AUTOSAR XML (schema 4-0-3)
standard types defined: uint8, Boolean, UInt16, UInt32, UInt8
package /AUTOSAR_Platform/DataConstrs
  range DC_Boolean: raw 0..1
  range DC_UInt16: raw 0..65535
  range DC_UInt8: raw 0..255
package /PATAC/Facility/DataTypes/Implementation
  compu method COMPU_Boolean: 0=FALSE, 1=TRUE
  unit NoUnit: factor-si-to-unit=1, offset-si-to-unit=0
package /PATAC/MSM/ComponentTypes
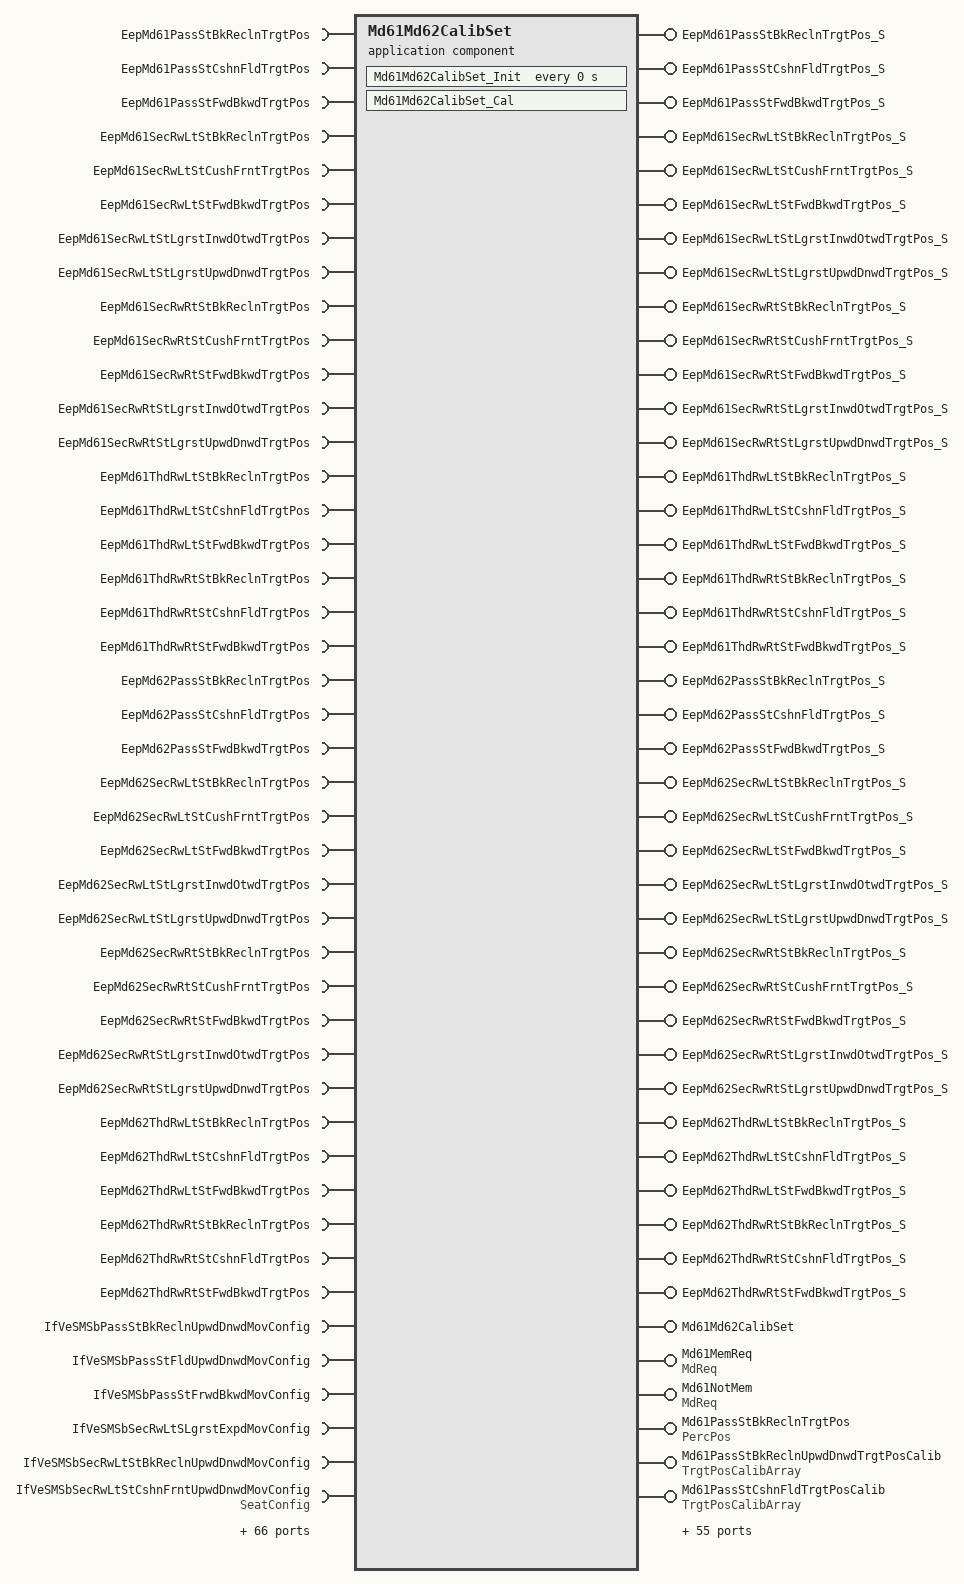
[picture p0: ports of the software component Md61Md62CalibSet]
  application sw component type Md61Md62CalibSet
    99 x provide port:
      EepMd61PassStBkReclnTrgtPos_S: nonqueued-sender-com-spec{data-element=EepMd61PassStBkReclnTrgtPos_S/Val, init-value=4095}, provided-interface=EepMd61PassStBkReclnTrgtPos_S
      EepMd61PassStCshnFldTrgtPos_S: nonqueued-sender-com-spec{data-element=EepMd61PassStCshnFldTrgtPos_S/Val, init-value=4095}, provided-interface=EepMd61PassStCshnFldTrgtPos_S
      EepMd61PassStFwdBkwdTrgtPos_S: nonqueued-sender-com-spec{data-element=EepMd61PassStFwdBkwdTrgtPos_S/Val, init-value=4095}, provided-interface=EepMd61PassStFwdBkwdTrgtPos_S
      EepMd61SecRwLtStBkReclnTrgtPos_S: nonqueued-sender-com-spec{data-element=EepMd61SecRwLtStBkReclnTrgtPos_S/Val, init-value=4095}, provided-interface=EepMd61SecRwLtStBkReclnTrgtPos_S
      EepMd61SecRwLtStCushFrntTrgtPos_S: nonqueued-sender-com-spec{data-element=EepMd61SecRwLtStCushFrntTrgtPos_S/Val, init-value=4095}, provided-interface=EepMd61SecRwLtStCushFrntTrgtPos_S
      EepMd61SecRwLtStFwdBkwdTrgtPos_S: nonqueued-sender-com-spec{data-element=EepMd61SecRwLtStFwdBkwdTrgtPos_S/Val, init-value=4095}, provided-interface=EepMd61SecRwLtStFwdBkwdTrgtPos_S
      EepMd61SecRwLtStLgrstInwdOtwdTrgtPos_S: nonqueued-sender-com-spec{data-element=EepMd61SecRwLtStLgrstInwdOtwdTrgtPos_S/Val, init-value=4095}, provided-interface=EepMd61SecRwLtStLgrstInwdOtwdTrgtPos_S
      EepMd61SecRwLtStLgrstUpwdDnwdTrgtPos_S: nonqueued-sender-com-spec{data-element=EepMd61SecRwLtStLgrstUpwdDnwdTrgtPos_S/Val, init-value=4095}, provided-interface=EepMd61SecRwLtStLgrstUpwdDnwdTrgtPos_S
      EepMd61SecRwRtStBkReclnTrgtPos_S: nonqueued-sender-com-spec{data-element=EepMd61SecRwRtStBkReclnTrgtPos_S/Val, init-value=4095}, provided-interface=EepMd61SecRwRtStBkReclnTrgtPos_S
      EepMd61SecRwRtStCushFrntTrgtPos_S: nonqueued-sender-com-spec{data-element=EepMd61SecRwRtStCushFrntTrgtPos_S/Val, init-value=4095}, provided-interface=EepMd61SecRwRtStCushFrntTrgtPos_S
      EepMd61SecRwRtStFwdBkwdTrgtPos_S: nonqueued-sender-com-spec{data-element=EepMd61SecRwRtStFwdBkwdTrgtPos_S/Val, init-value=4095}, provided-interface=EepMd61SecRwRtStFwdBkwdTrgtPos_S
      EepMd61SecRwRtStLgrstInwdOtwdTrgtPos_S: nonqueued-sender-com-spec{data-element=EepMd61SecRwRtStLgrstInwdOtwdTrgtPos_S/Val, init-value=4095}, provided-interface=EepMd61SecRwRtStLgrstInwdOtwdTrgtPos_S
      EepMd61SecRwRtStLgrstUpwdDnwdTrgtPos_S: nonqueued-sender-com-spec{data-element=EepMd61SecRwRtStLgrstUpwdDnwdTrgtPos_S/Val, init-value=4095}, provided-interface=EepMd61SecRwRtStLgrstUpwdDnwdTrgtPos_S
      EepMd61ThdRwLtStBkReclnTrgtPos_S: nonqueued-sender-com-spec{data-element=EepMd61ThdRwLtStBkReclnTrgtPos_S/Val, init-value=4095}, provided-interface=EepMd61ThdRwLtStBkReclnTrgtPos_S
      EepMd61ThdRwLtStCshnFldTrgtPos_S: nonqueued-sender-com-spec{data-element=EepMd61ThdRwLtStCshnFldTrgtPos_S/Val, init-value=4095}, provided-interface=EepMd61ThdRwLtStCshnFldTrgtPos_S
      EepMd61ThdRwLtStFwdBkwdTrgtPos_S: nonqueued-sender-com-spec{data-element=EepMd61ThdRwLtStFwdBkwdTrgtPos_S/Val, init-value=4095}, provided-interface=EepMd61ThdRwLtStFwdBkwdTrgtPos_S
      EepMd61ThdRwRtStBkReclnTrgtPos_S: nonqueued-sender-com-spec{data-element=EepMd61ThdRwRtStBkReclnTrgtPos_S/Val, init-value=4095}, provided-interface=EepMd61ThdRwRtStBkReclnTrgtPos_S
      EepMd61ThdRwRtStCshnFldTrgtPos_S: nonqueued-sender-com-spec{data-element=EepMd61ThdRwRtStCshnFldTrgtPos_S/Val, init-value=4095}, provided-interface=EepMd61ThdRwRtStCshnFldTrgtPos_S
      EepMd61ThdRwRtStFwdBkwdTrgtPos_S: nonqueued-sender-com-spec{data-element=EepMd61ThdRwRtStFwdBkwdTrgtPos_S/Val, init-value=4095}, provided-interface=EepMd61ThdRwRtStFwdBkwdTrgtPos_S
      EepMd62PassStBkReclnTrgtPos_S: nonqueued-sender-com-spec{data-element=EepMd62PassStBkReclnTrgtPos_S/Val, init-value=4095}, provided-interface=EepMd62PassStBkReclnTrgtPos_S
      EepMd62PassStCshnFldTrgtPos_S: nonqueued-sender-com-spec{data-element=EepMd62PassStCshnFldTrgtPos_S/Val, init-value=4095}, provided-interface=EepMd62PassStCshnFldTrgtPos_S
      EepMd62PassStFwdBkwdTrgtPos_S: nonqueued-sender-com-spec{data-element=EepMd62PassStFwdBkwdTrgtPos_S/Val, init-value=4095}, provided-interface=EepMd62PassStFwdBkwdTrgtPos_S
      EepMd62SecRwLtStBkReclnTrgtPos_S: nonqueued-sender-com-spec{data-element=EepMd62SecRwLtStBkReclnTrgtPos_S/Val, init-value=4095}, provided-interface=EepMd62SecRwLtStBkReclnTrgtPos_S
      EepMd62SecRwLtStCushFrntTrgtPos_S: nonqueued-sender-com-spec{data-element=EepMd62SecRwLtStCushFrntTrgtPos_S/Val, init-value=4095}, provided-interface=EepMd62SecRwLtStCushFrntTrgtPos_S
      EepMd62SecRwLtStFwdBkwdTrgtPos_S: nonqueued-sender-com-spec{data-element=EepMd62SecRwLtStFwdBkwdTrgtPos_S/Val, init-value=4095}, provided-interface=EepMd62SecRwLtStFwdBkwdTrgtPos_S
      EepMd62SecRwLtStLgrstInwdOtwdTrgtPos_S: nonqueued-sender-com-spec{data-element=EepMd62SecRwLtStLgrstInwdOtwdTrgtPos_S/Val, init-value=4095}, provided-interface=EepMd62SecRwLtStLgrstInwdOtwdTrgtPos_S
      EepMd62SecRwLtStLgrstUpwdDnwdTrgtPos_S: nonqueued-sender-com-spec{data-element=EepMd62SecRwLtStLgrstUpwdDnwdTrgtPos_S/Val, init-value=4095}, provided-interface=EepMd62SecRwLtStLgrstUpwdDnwdTrgtPos_S
      EepMd62SecRwRtStBkReclnTrgtPos_S: nonqueued-sender-com-spec{data-element=EepMd62SecRwRtStBkReclnTrgtPos_S/Val, init-value=4095}, provided-interface=EepMd62SecRwRtStBkReclnTrgtPos_S
      EepMd62SecRwRtStCushFrntTrgtPos_S: nonqueued-sender-com-spec{data-element=EepMd62SecRwRtStCushFrntTrgtPos_S/Val, init-value=4095}, provided-interface=EepMd62SecRwRtStCushFrntTrgtPos_S
      EepMd62SecRwRtStFwdBkwdTrgtPos_S: nonqueued-sender-com-spec{data-element=EepMd62SecRwRtStFwdBkwdTrgtPos_S/Val, init-value=4095}, provided-interface=EepMd62SecRwRtStFwdBkwdTrgtPos_S
      EepMd62SecRwRtStLgrstInwdOtwdTrgtPos_S: nonqueued-sender-com-spec{data-element=EepMd62SecRwRtStLgrstInwdOtwdTrgtPos_S/Val, init-value=4095}, provided-interface=EepMd62SecRwRtStLgrstInwdOtwdTrgtPos_S
      EepMd62SecRwRtStLgrstUpwdDnwdTrgtPos_S: nonqueued-sender-com-spec{data-element=EepMd62SecRwRtStLgrstUpwdDnwdTrgtPos_S/Val, init-value=4095}, provided-interface=EepMd62SecRwRtStLgrstUpwdDnwdTrgtPos_S
      EepMd62ThdRwLtStBkReclnTrgtPos_S: nonqueued-sender-com-spec{data-element=EepMd62ThdRwLtStBkReclnTrgtPos_S/Val, init-value=4095}, provided-interface=EepMd62ThdRwLtStBkReclnTrgtPos_S
      EepMd62ThdRwLtStCshnFldTrgtPos_S: nonqueued-sender-com-spec{data-element=EepMd62ThdRwLtStCshnFldTrgtPos_S/Val, init-value=4095}, provided-interface=EepMd62ThdRwLtStCshnFldTrgtPos_S
      EepMd62ThdRwLtStFwdBkwdTrgtPos_S: nonqueued-sender-com-spec{data-element=EepMd62ThdRwLtStFwdBkwdTrgtPos_S/Val, init-value=4095}, provided-interface=EepMd62ThdRwLtStFwdBkwdTrgtPos_S
      EepMd62ThdRwRtStBkReclnTrgtPos_S: nonqueued-sender-com-spec{data-element=EepMd62ThdRwRtStBkReclnTrgtPos_S/Val, init-value=4095}, provided-interface=EepMd62ThdRwRtStBkReclnTrgtPos_S
      EepMd62ThdRwRtStCshnFldTrgtPos_S: nonqueued-sender-com-spec{data-element=EepMd62ThdRwRtStCshnFldTrgtPos_S/Val, init-value=4095}, provided-interface=EepMd62ThdRwRtStCshnFldTrgtPos_S
      EepMd62ThdRwRtStFwdBkwdTrgtPos_S: nonqueued-sender-com-spec{data-element=EepMd62ThdRwRtStFwdBkwdTrgtPos_S/Val, init-value=4095}, provided-interface=EepMd62ThdRwRtStFwdBkwdTrgtPos_S
      Md61Md62CalibSet: server-com-spec{operation=Cal, queue-length=1}, provided-interface=Md61Md62CalibSet
      Md61MemReq: nonqueued-sender-com-spec{data-element=MdReq/Val, init-value=0}, provided-interface=MdReq
      Md61NotMem: nonqueued-sender-com-spec{data-element=MdReq/Val, init-value=0}, provided-interface=MdReq
      Md61PassStBkReclnTrgtPos: nonqueued-sender-com-spec{data-element=PercPos/Val, init-value=0}, provided-interface=PercPos
      Md61PassStBkReclnUpwdDnwdTrgtPosCalib: nonqueued-sender-com-spec{data-element=TrgtPosArray, init-value=[4095, 4095, 4095]}, provided-interface=TrgtPosCalibArray
      Md61PassStCshnFldTrgtPosCalib: nonqueued-sender-com-spec{data-element=TrgtPosArray, init-value=[4095, 4095, 4095]}, provided-interface=TrgtPosCalibArray
      Md61PassStFwdBkwdTrgtPosCalib: nonqueued-sender-com-spec{data-element=TrgtPosArray, init-value=[4095, 4095, 4095]}, provided-interface=TrgtPosCalibArray
      Md61PassStNeedFldOpn: nonqueued-sender-com-spec{data-element=TrgtIsFld/Val, init-value=0}, provided-interface=TrgtIsFld
      Md61PassStTrgtIsFld: nonqueued-sender-com-spec{data-element=TrgtIsFld/Val, init-value=0}, provided-interface=TrgtIsFld
      Md61SecRwLtStBkReclnTrgtPosCalib: nonqueued-sender-com-spec{data-element=TrgtPosArray, init-value=[4095, 4095, 4095]}, provided-interface=TrgtPosCalibArray
      Md61SecRwLtStCushFrntTrgtPosCalib: nonqueued-sender-com-spec{data-element=TrgtPosArray, init-value=[4095, 4095, 4095]}, provided-interface=TrgtPosCalibArray
      Md61SecRwLtStFwdBkwdCalib: nonqueued-sender-com-spec{data-element=TrgtPosArray, init-value=[4095, 4095, 4095]}, provided-interface=TrgtPosCalibArray
      Md61SecRwLtStLgrstInwdOtwdTrgtPosCalib: nonqueued-sender-com-spec{data-element=TrgtPosArray, init-value=[4095, 4095, 4095]}, provided-interface=TrgtPosCalibArray
      Md61SecRwLtStLgrstUpwdDnwdTrgtPosCalib: nonqueued-sender-com-spec{data-element=TrgtPosArray, init-value=[4095, 4095, 4095]}, provided-interface=TrgtPosCalibArray
      Md61SecRwRtStBkReclnTrgtPosCalib: nonqueued-sender-com-spec{data-element=TrgtPosArray, init-value=[4095, 4095, 4095]}, provided-interface=TrgtPosCalibArray
      Md61SecRwRtStCushFrntTrgtPosCalib: nonqueued-sender-com-spec{data-element=TrgtPosArray, init-value=[4095, 4095, 4095]}, provided-interface=TrgtPosCalibArray
      Md61SecRwRtStFwdBkwdCalib: nonqueued-sender-com-spec{data-element=TrgtPosArray, init-value=[4095, 4095, 4095]}, provided-interface=TrgtPosCalibArray
      Md61SecRwRtStLgrstInwdOtwdTrgtPosCalib: nonqueued-sender-com-spec{data-element=TrgtPosArray, init-value=[4095, 4095, 4095]}, provided-interface=TrgtPosCalibArray
      Md61SecRwRtStLgrstUpwdDnwdTrgtPosCalib: nonqueued-sender-com-spec{data-element=TrgtPosArray, init-value=[4095, 4095, 4095]}, provided-interface=TrgtPosCalibArray
      Md61ThdRwLtStBkReclnUpwdDnwdTrgtPosCalib: nonqueued-sender-com-spec{data-element=TrgtPosArray, init-value=[4095, 4095, 4095]}, provided-interface=TrgtPosCalibArray
      Md61ThdRwLtStCshnFldUpwdDnwdTrgtPos: nonqueued-sender-com-spec{data-element=PercPos/Val, init-value=0}, provided-interface=PercPos
      Md61ThdRwLtStCshnFldUpwdDnwdTrgtPosCalib: nonqueued-sender-com-spec{data-element=TrgtPosArray, init-value=[4095, 4095, 4095]}, provided-interface=TrgtPosCalibArray
      Md61ThdRwLtStFrwdBkwdPosTrgtPosCalib: nonqueued-sender-com-spec{data-element=TrgtPosArray, init-value=[4095, 4095, 4095]}, provided-interface=TrgtPosCalibArray
      Md61ThdRwLtStNeedFldOpn: nonqueued-sender-com-spec{data-element=TrgtIsFld/Val, init-value=0}, provided-interface=TrgtIsFld
      Md61ThdRwLtStTrgtIsFld: nonqueued-sender-com-spec{data-element=TrgtIsFld/Val, init-value=0}, provided-interface=TrgtIsFld
      Md61ThdRwRtStBkReclnUpwdDnwdTrgtPosCalib: nonqueued-sender-com-spec{data-element=TrgtPosArray, init-value=[4095, 4095, 4095]}, provided-interface=TrgtPosCalibArray
      Md61ThdRwRtStCshnFldUpwdDnwdTrgtPos: nonqueued-sender-com-spec{data-element=PercPos/Val, init-value=0}, provided-interface=PercPos
      Md61ThdRwRtStCshnFldUpwdDnwdTrgtPosCalib: nonqueued-sender-com-spec{data-element=TrgtPosArray, init-value=[4095, 4095, 4095]}, provided-interface=TrgtPosCalibArray
      Md61ThdRwRtStFrwdBkwdPosTrgtPosCalib: nonqueued-sender-com-spec{data-element=TrgtPosArray, init-value=[4095, 4095, 4095]}, provided-interface=TrgtPosCalibArray
      Md61ThdRwRtStNeedFldOpn: nonqueued-sender-com-spec{data-element=TrgtIsFld/Val, init-value=0}, provided-interface=TrgtIsFld
      Md61ThdRwRtStTrgtIsFld: nonqueued-sender-com-spec{data-element=TrgtIsFld/Val, init-value=0}, provided-interface=TrgtIsFld
      Md62MemReq: nonqueued-sender-com-spec{data-element=MdReq/Val, init-value=0}, provided-interface=MdReq
      Md62NotMem: nonqueued-sender-com-spec{data-element=MdReq/Val, init-value=0}, provided-interface=MdReq
      Md62PassStBkReclnTrgtPos: nonqueued-sender-com-spec{data-element=PercPos/Val, init-value=0}, provided-interface=PercPos
      Md62PassStBkReclnTrgtPosCalib: nonqueued-sender-com-spec{data-element=TrgtPosArray, init-value=[4095, 4095, 4095]}, provided-interface=TrgtPosCalibArray
      Md62PassStCshnFldTrgtPosCalib: nonqueued-sender-com-spec{data-element=TrgtPosArray, init-value=[4095, 4095, 4095]}, provided-interface=TrgtPosCalibArray
      Md62PassStFwdBkwdTrgtPosCalib: nonqueued-sender-com-spec{data-element=TrgtPosArray, init-value=[4095, 4095, 4095]}, provided-interface=TrgtPosCalibArray
      Md62PassStNeedFldOpn: nonqueued-sender-com-spec{data-element=TrgtIsFld/Val, init-value=0}, provided-interface=TrgtIsFld
      Md62PassStTrgtIsFld: nonqueued-sender-com-spec{data-element=TrgtIsFld/Val, init-value=0}, provided-interface=TrgtIsFld
      Md62SecRwLtStBkReclnTrgtPosCalib: nonqueued-sender-com-spec{data-element=TrgtPosArray, init-value=[4095, 4095, 4095]}, provided-interface=TrgtPosCalibArray
      Md62SecRwLtStCushFrntTrgtPosCalib: nonqueued-sender-com-spec{data-element=TrgtPosArray, init-value=[4095, 4095, 4095]}, provided-interface=TrgtPosCalibArray
      Md62SecRwLtStFwdBkwdCalib: nonqueued-sender-com-spec{data-element=TrgtPosArray, init-value=[4095, 4095, 4095]}, provided-interface=TrgtPosCalibArray
      Md62SecRwLtStLgrstInwdOtwdTrgtPosCalib: nonqueued-sender-com-spec{data-element=TrgtPosArray, init-value=[4095, 4095, 4095]}, provided-interface=TrgtPosCalibArray
      Md62SecRwLtStLgrstUpwdDnwdTrgtPosCalib: nonqueued-sender-com-spec{data-element=TrgtPosArray, init-value=[4095, 4095, 4095]}, provided-interface=TrgtPosCalibArray
      Md62SecRwRtStBkReclnTrgtPosCalib: nonqueued-sender-com-spec{data-element=TrgtPosArray, init-value=[4095, 4095, 4095]}, provided-interface=TrgtPosCalibArray
      Md62SecRwRtStCushFrntTrgtPosCalib: nonqueued-sender-com-spec{data-element=TrgtPosArray, init-value=[4095, 4095, 4095]}, provided-interface=TrgtPosCalibArray
      Md62SecRwRtStFwdBkwdCalib: nonqueued-sender-com-spec{data-element=TrgtPosArray, init-value=[4095, 4095, 4095]}, provided-interface=TrgtPosCalibArray
      Md62SecRwRtStLgrstInwdOtwdTrgtPosCalib: nonqueued-sender-com-spec{data-element=TrgtPosArray, init-value=[4095, 4095, 4095]}, provided-interface=TrgtPosCalibArray
      Md62SecRwRtStLgrstUpwdDnwdTrgtPosCalib: nonqueued-sender-com-spec{data-element=TrgtPosArray, init-value=[4095, 4095, 4095]}, provided-interface=TrgtPosCalibArray
      Md62ThdRwLtStBkReclnUpwdDnwdTrgtPosCalib: nonqueued-sender-com-spec{data-element=TrgtPosArray, init-value=[4095, 4095, 4095]}, provided-interface=TrgtPosCalibArray
      Md62ThdRwLtStCshnFldUpwdDnwdTrgtPos: nonqueued-sender-com-spec{data-element=PercPos/Val, init-value=0}, provided-interface=PercPos
      Md62ThdRwLtStCshnFldUpwdDnwdTrgtPosCalib: nonqueued-sender-com-spec{data-element=TrgtPosArray, init-value=[4095, 4095, 4095]}, provided-interface=TrgtPosCalibArray
      Md62ThdRwLtStFrwdBkwdPosTrgtPosCalib: nonqueued-sender-com-spec{data-element=TrgtPosArray, init-value=[4095, 4095, 4095]}, provided-interface=TrgtPosCalibArray
      Md62ThdRwLtStNeedFldOpn: nonqueued-sender-com-spec{data-element=TrgtIsFld/Val, init-value=0}, provided-interface=TrgtIsFld
      Md62ThdRwLtStTrgtIsFld: nonqueued-sender-com-spec{data-element=TrgtIsFld/Val, init-value=0}, provided-interface=TrgtIsFld
      Md62ThdRwRtStBkReclnUpwdDnwdTrgtPosCalib: nonqueued-sender-com-spec{data-element=TrgtPosArray, init-value=[4095, 4095, 4095]}, provided-interface=TrgtPosCalibArray
      Md62ThdRwRtStCshnFldUpwdDnwdTrgtPos: nonqueued-sender-com-spec{data-element=PercPos/Val, init-value=0}, provided-interface=PercPos
      Md62ThdRwRtStCshnFldUpwdDnwdTrgtPosCalib: nonqueued-sender-com-spec{data-element=TrgtPosArray, init-value=[4095, 4095, 4095]}, provided-interface=TrgtPosCalibArray
      Md62ThdRwRtStFrwdBkwdPosTrgtPosCalib: nonqueued-sender-com-spec{data-element=TrgtPosArray, init-value=[4095, 4095, 4095]}, provided-interface=TrgtPosCalibArray
      Md62ThdRwRtStNeedFldOpn: nonqueued-sender-com-spec{data-element=TrgtIsFld/Val, init-value=0}, provided-interface=TrgtIsFld
      Md62ThdRwRtStTrgtIsFld: nonqueued-sender-com-spec{data-element=TrgtIsFld/Val, init-value=0}, provided-interface=TrgtIsFld
    110 x require port:
      EepMd61PassStBkReclnTrgtPos: nonqueued-receiver-com-spec{data-element=EepMd61PassStBkReclnTrgtPos/Val, filter=data-filter-type=ALWAYS, init-value=4095}, required-interface=EepMd61PassStBkReclnTrgtPos
      EepMd61PassStCshnFldTrgtPos: nonqueued-receiver-com-spec{data-element=EepMd61PassStCshnFldTrgtPos/Val, filter=data-filter-type=ALWAYS, init-value=4095}, required-interface=EepMd61PassStCshnFldTrgtPos
      EepMd61PassStFwdBkwdTrgtPos: nonqueued-receiver-com-spec{data-element=EepMd61PassStFwdBkwdTrgtPos/Val, filter=data-filter-type=ALWAYS, init-value=4095}, required-interface=EepMd61PassStFwdBkwdTrgtPos
      EepMd61SecRwLtStBkReclnTrgtPos: nonqueued-receiver-com-spec{data-element=EepMd61SecRwLtStBkReclnTrgtPos/Val, filter=data-filter-type=ALWAYS, init-value=4095}, required-interface=EepMd61SecRwLtStBkReclnTrgtPos
      EepMd61SecRwLtStCushFrntTrgtPos: nonqueued-receiver-com-spec{data-element=EepMd61SecRwLtStCushFrntTrgtPos/Val, filter=data-filter-type=ALWAYS, init-value=4095}, required-interface=EepMd61SecRwLtStCushFrntTrgtPos
      EepMd61SecRwLtStFwdBkwdTrgtPos: nonqueued-receiver-com-spec{data-element=EepMd61SecRwLtStFwdBkwdTrgtPos/Val, filter=data-filter-type=ALWAYS, init-value=4095}, required-interface=EepMd61SecRwLtStFwdBkwdTrgtPos
      EepMd61SecRwLtStLgrstInwdOtwdTrgtPos: nonqueued-receiver-com-spec{data-element=EepMd61SecRwLtStLgrstInwdOtwdTrgtPos/Val, filter=data-filter-type=ALWAYS, init-value=4095}, required-interface=EepMd61SecRwLtStLgrstInwdOtwdTrgtPos
      EepMd61SecRwLtStLgrstUpwdDnwdTrgtPos: nonqueued-receiver-com-spec{data-element=EepMd61SecRwLtStLgrstUpwdDnwdTrgtPos/Val, filter=data-filter-type=ALWAYS, init-value=4095}, required-interface=EepMd61SecRwLtStLgrstUpwdDnwdTrgtPos
      EepMd61SecRwRtStBkReclnTrgtPos: nonqueued-receiver-com-spec{data-element=EepMd61SecRwRtStBkReclnTrgtPos/Val, filter=data-filter-type=ALWAYS, init-value=4095}, required-interface=EepMd61SecRwRtStBkReclnTrgtPos
      EepMd61SecRwRtStCushFrntTrgtPos: nonqueued-receiver-com-spec{data-element=EepMd61SecRwRtStCushFrntTrgtPos/Val, filter=data-filter-type=ALWAYS, init-value=4095}, required-interface=EepMd61SecRwRtStCushFrntTrgtPos
      EepMd61SecRwRtStFwdBkwdTrgtPos: nonqueued-receiver-com-spec{data-element=EepMd61SecRwRtStFwdBkwdTrgtPos/Val, filter=data-filter-type=ALWAYS, init-value=4095}, required-interface=EepMd61SecRwRtStFwdBkwdTrgtPos
      EepMd61SecRwRtStLgrstInwdOtwdTrgtPos: nonqueued-receiver-com-spec{data-element=EepMd61SecRwRtStLgrstInwdOtwdTrgtPos/Val, filter=data-filter-type=ALWAYS, init-value=4095}, required-interface=EepMd61SecRwRtStLgrstInwdOtwdTrgtPos
      EepMd61SecRwRtStLgrstUpwdDnwdTrgtPos: nonqueued-receiver-com-spec{data-element=EepMd61SecRwRtStLgrstUpwdDnwdTrgtPos/Val, filter=data-filter-type=ALWAYS, init-value=4095}, required-interface=EepMd61SecRwRtStLgrstUpwdDnwdTrgtPos
      EepMd61ThdRwLtStBkReclnTrgtPos: nonqueued-receiver-com-spec{data-element=EepMd61ThdRwLtStBkReclnTrgtPos/Val, filter=data-filter-type=ALWAYS, init-value=4095}, required-interface=EepMd61ThdRwLtStBkReclnTrgtPos
      EepMd61ThdRwLtStCshnFldTrgtPos: nonqueued-receiver-com-spec{data-element=EepMd61ThdRwLtStCshnFldTrgtPos/Val, filter=data-filter-type=ALWAYS, init-value=4095}, required-interface=EepMd61ThdRwLtStCshnFldTrgtPos
      EepMd61ThdRwLtStFwdBkwdTrgtPos: nonqueued-receiver-com-spec{data-element=EepMd61ThdRwLtStFwdBkwdTrgtPos/Val, filter=data-filter-type=ALWAYS, init-value=4095}, required-interface=EepMd61ThdRwLtStFwdBkwdTrgtPos
      EepMd61ThdRwRtStBkReclnTrgtPos: nonqueued-receiver-com-spec{data-element=EepMd61ThdRwRtStBkReclnTrgtPos/Val, filter=data-filter-type=ALWAYS, init-value=4095}, required-interface=EepMd61ThdRwRtStBkReclnTrgtPos
      EepMd61ThdRwRtStCshnFldTrgtPos: nonqueued-receiver-com-spec{data-element=EepMd61ThdRwRtStCshnFldTrgtPos/Val, filter=data-filter-type=ALWAYS, init-value=4095}, required-interface=EepMd61ThdRwRtStCshnFldTrgtPos
      EepMd61ThdRwRtStFwdBkwdTrgtPos: nonqueued-receiver-com-spec{data-element=EepMd61ThdRwRtStFwdBkwdTrgtPos/Val, filter=data-filter-type=ALWAYS, init-value=4095}, required-interface=EepMd61ThdRwRtStFwdBkwdTrgtPos
      EepMd62PassStBkReclnTrgtPos: nonqueued-receiver-com-spec{data-element=EepMd62PassStBkReclnTrgtPos/Val, filter=data-filter-type=ALWAYS, init-value=4095}, required-interface=EepMd62PassStBkReclnTrgtPos
      EepMd62PassStCshnFldTrgtPos: nonqueued-receiver-com-spec{data-element=EepMd62PassStCshnFldTrgtPos/Val, filter=data-filter-type=ALWAYS, init-value=4095}, required-interface=EepMd62PassStCshnFldTrgtPos
      EepMd62PassStFwdBkwdTrgtPos: nonqueued-receiver-com-spec{data-element=EepMd62PassStFwdBkwdTrgtPos/Val, filter=data-filter-type=ALWAYS, init-value=4095}, required-interface=EepMd62PassStFwdBkwdTrgtPos
      EepMd62SecRwLtStBkReclnTrgtPos: nonqueued-receiver-com-spec{data-element=EepMd62SecRwLtStBkReclnTrgtPos/Val, filter=data-filter-type=ALWAYS, init-value=4095}, required-interface=EepMd62SecRwLtStBkReclnTrgtPos
      EepMd62SecRwLtStCushFrntTrgtPos: nonqueued-receiver-com-spec{data-element=EepMd62SecRwLtStCushFrntTrgtPos/Val, filter=data-filter-type=ALWAYS, init-value=4095}, required-interface=EepMd62SecRwLtStCushFrntTrgtPos
      EepMd62SecRwLtStFwdBkwdTrgtPos: nonqueued-receiver-com-spec{data-element=EepMd62SecRwLtStFwdBkwdTrgtPos/Val, filter=data-filter-type=ALWAYS, init-value=4095}, required-interface=EepMd62SecRwLtStFwdBkwdTrgtPos
      EepMd62SecRwLtStLgrstInwdOtwdTrgtPos: nonqueued-receiver-com-spec{data-element=EepMd62SecRwLtStLgrstInwdOtwdTrgtPos/Val, filter=data-filter-type=ALWAYS, init-value=4095}, required-interface=EepMd62SecRwLtStLgrstInwdOtwdTrgtPos
      EepMd62SecRwLtStLgrstUpwdDnwdTrgtPos: nonqueued-receiver-com-spec{data-element=EepMd62SecRwLtStLgrstUpwdDnwdTrgtPos/Val, filter=data-filter-type=ALWAYS, init-value=4095}, required-interface=EepMd62SecRwLtStLgrstUpwdDnwdTrgtPos
      EepMd62SecRwRtStBkReclnTrgtPos: nonqueued-receiver-com-spec{data-element=EepMd62SecRwRtStBkReclnTrgtPos/Val, filter=data-filter-type=ALWAYS, init-value=4095}, required-interface=EepMd62SecRwRtStBkReclnTrgtPos
      EepMd62SecRwRtStCushFrntTrgtPos: nonqueued-receiver-com-spec{data-element=EepMd62SecRwRtStCushFrntTrgtPos/Val, filter=data-filter-type=ALWAYS, init-value=4095}, required-interface=EepMd62SecRwRtStCushFrntTrgtPos
      EepMd62SecRwRtStFwdBkwdTrgtPos: nonqueued-receiver-com-spec{data-element=EepMd62SecRwRtStFwdBkwdTrgtPos/Val, filter=data-filter-type=ALWAYS, init-value=4095}, required-interface=EepMd62SecRwRtStFwdBkwdTrgtPos
      EepMd62SecRwRtStLgrstInwdOtwdTrgtPos: nonqueued-receiver-com-spec{data-element=EepMd62SecRwRtStLgrstInwdOtwdTrgtPos/Val, filter=data-filter-type=ALWAYS, init-value=4095}, required-interface=EepMd62SecRwRtStLgrstInwdOtwdTrgtPos
      EepMd62SecRwRtStLgrstUpwdDnwdTrgtPos: nonqueued-receiver-com-spec{data-element=EepMd62SecRwRtStLgrstUpwdDnwdTrgtPos/Val, filter=data-filter-type=ALWAYS, init-value=4095}, required-interface=EepMd62SecRwRtStLgrstUpwdDnwdTrgtPos
      EepMd62ThdRwLtStBkReclnTrgtPos: nonqueued-receiver-com-spec{data-element=EepMd62ThdRwLtStBkReclnTrgtPos/Val, filter=data-filter-type=ALWAYS, init-value=4095}, required-interface=EepMd62ThdRwLtStBkReclnTrgtPos
      EepMd62ThdRwLtStCshnFldTrgtPos: nonqueued-receiver-com-spec{data-element=EepMd62ThdRwLtStCshnFldTrgtPos/Val, filter=data-filter-type=ALWAYS, init-value=4095}, required-interface=EepMd62ThdRwLtStCshnFldTrgtPos
      EepMd62ThdRwLtStFwdBkwdTrgtPos: nonqueued-receiver-com-spec{data-element=EepMd62ThdRwLtStFwdBkwdTrgtPos/Val, filter=data-filter-type=ALWAYS, init-value=4095}, required-interface=EepMd62ThdRwLtStFwdBkwdTrgtPos
      EepMd62ThdRwRtStBkReclnTrgtPos: nonqueued-receiver-com-spec{data-element=EepMd62ThdRwRtStBkReclnTrgtPos/Val, filter=data-filter-type=ALWAYS, init-value=4095}, required-interface=EepMd62ThdRwRtStBkReclnTrgtPos
      EepMd62ThdRwRtStCshnFldTrgtPos: nonqueued-receiver-com-spec{data-element=EepMd62ThdRwRtStCshnFldTrgtPos/Val, filter=data-filter-type=ALWAYS, init-value=4095}, required-interface=EepMd62ThdRwRtStCshnFldTrgtPos
      EepMd62ThdRwRtStFwdBkwdTrgtPos: nonqueued-receiver-com-spec{data-element=EepMd62ThdRwRtStFwdBkwdTrgtPos/Val, filter=data-filter-type=ALWAYS, init-value=4095}, required-interface=EepMd62ThdRwRtStFwdBkwdTrgtPos
      IfVeSMSbPassStBkReclnUpwdDnwdMovConfig: nonqueued-receiver-com-spec{data-element=IfVeSMSbPassStBkReclnUpwdDnwdMovConfig/Val, filter=data-filter-type=ALWAYS, init-value=0}, required-interface=IfVeSMSbPassStBkReclnUpwdDnwdMovConfig
      IfVeSMSbPassStFldUpwdDnwdMovConfig: nonqueued-receiver-com-spec{data-element=IfVeSMSbPassStFldUpwdDnwdMovConfig/Val, filter=data-filter-type=ALWAYS, init-value=0}, required-interface=IfVeSMSbPassStFldUpwdDnwdMovConfig
      IfVeSMSbPassStFrwdBkwdMovConfig: nonqueued-receiver-com-spec{data-element=IfVeSMSbPassStFrwdBkwdMovConfig/Val, filter=data-filter-type=ALWAYS, init-value=0}, required-interface=IfVeSMSbPassStFrwdBkwdMovConfig
      IfVeSMSbSecRwLtSLgrstExpdMovConfig: nonqueued-receiver-com-spec{data-element=IfVeSMSbSecRwLtSLgrstExpdMovConfig/Val, filter=data-filter-type=ALWAYS, init-value=1}, required-interface=IfVeSMSbSecRwLtSLgrstExpdMovConfig
      IfVeSMSbSecRwLtStBkReclnUpwdDnwdMovConfig: nonqueued-receiver-com-spec{data-element=IfVeSMSbSecRwLtStBkReclnUpwdDnwdMovConfig/Val, filter=data-filter-type=ALWAYS, init-value=0}, required-interface=IfVeSMSbSecRwLtStBkReclnUpwdDnwdMovConfig
      IfVeSMSbSecRwLtStCshnFrntUpwdDnwdMovConfig: nonqueued-receiver-com-spec{data-element=SeatConfig/Val, filter=data-filter-type=ALWAYS, init-value=0}, required-interface=SeatConfig
      IfVeSMSbSecRwLtStFrwdBkwdMovConfig: nonqueued-receiver-com-spec{data-element=IfVeSMSbSecRwLtStFrwdBkwdMovConfig/Val, filter=data-filter-type=ALWAYS, init-value=0}, required-interface=IfVeSMSbSecRwLtStFrwdBkwdMovConfig
      IfVeSMSbSecRwLtStLgrstUpwdMovConfig: nonqueued-receiver-com-spec{data-element=IfVeSMSbSecRwLtStLgrstUpwdMovConfig/Val, filter=data-filter-type=ALWAYS, init-value=0}, required-interface=IfVeSMSbSecRwLtStLgrstUpwdMovConfig
      IfVeSMSbSecRwRtSLgrstExpdMovConfig: nonqueued-receiver-com-spec{data-element=IfVeSMSbSecRwRtSLgrstExpdMovConfig/Val, filter=data-filter-type=ALWAYS, init-value=0}, required-interface=IfVeSMSbSecRwRtSLgrstExpdMovConfig
      IfVeSMSbSecRwRtStBkReclnUpwdDnwdMovConfig: nonqueued-receiver-com-spec{data-element=IfVeSMSbSecRwRtStBkReclnUpwdDnwdMovConfig/Val, filter=data-filter-type=ALWAYS, init-value=0}, required-interface=IfVeSMSbSecRwRtStBkReclnUpwdDnwdMovConfig
      IfVeSMSbSecRwRtStCshnFrntUpwdDnwdMovConfig: nonqueued-receiver-com-spec{data-element=SeatConfig/Val, filter=data-filter-type=ALWAYS, init-value=0}, required-interface=SeatConfig
      IfVeSMSbSecRwRtStFrwdBkwdMovConfig: nonqueued-receiver-com-spec{data-element=IfVeSMSbSecRwRtStFrwdBkwdMovConfig/Val, filter=data-filter-type=ALWAYS, init-value=0}, required-interface=IfVeSMSbSecRwRtStFrwdBkwdMovConfig
      IfVeSMSbSecRwRtStLgrstUpwdMovConfig: nonqueued-receiver-com-spec{data-element=IfVeSMSbSecRwRtStLgrstUpwdMovConfig/Val, filter=data-filter-type=ALWAYS, init-value=0}, required-interface=IfVeSMSbSecRwRtStLgrstUpwdMovConfig
      IfVeSMSbThdRwLtStBkReclnUpwdDnwdMovConfig: nonqueued-receiver-com-spec{data-element=IfVeSMSbThdRwLtStBkReclnUpwdDnwdMovConfig/Val, filter=data-filter-type=ALWAYS, init-value=0}, required-interface=IfVeSMSbThdRwLtStBkReclnUpwdDnwdMovConfig
      IfVeSMSbThdRwLtStCshnFldUpwdDnwdMovConfig: nonqueued-receiver-com-spec{data-element=IfVeSMSbThdRwLtStCshnFldUpwdDnwdMovConfig/Val, filter=data-filter-type=ALWAYS, init-value=0}, required-interface=IfVeSMSbThdRwLtStCshnFldUpwdDnwdMovConfig
      IfVeSMSbThdRwLtStFrwdBkwdMovConfig: nonqueued-receiver-com-spec{data-element=IfVeSMSbThdRwLtStFrwdBkwdMovConfig/Val, filter=data-filter-type=ALWAYS, init-value=0}, required-interface=IfVeSMSbThdRwLtStFrwdBkwdMovConfig
      IfVeSMSbThdRwRtStBkReclnUpwdDnwdMovConfig: nonqueued-receiver-com-spec{data-element=IfVeSMSbThdRwRtStBkReclnUpwdDnwdMovConfig/Val, filter=data-filter-type=ALWAYS, init-value=0}, required-interface=IfVeSMSbThdRwRtStBkReclnUpwdDnwdMovConfig
      IfVeSMSbThdRwRtStCshnFldUpwdDnwdMovConfig: nonqueued-receiver-com-spec{data-element=IfVeSMSbThdRwRtStCshnFldUpwdDnwdMovConfig/Val, filter=data-filter-type=ALWAYS, init-value=0}, required-interface=IfVeSMSbThdRwRtStCshnFldUpwdDnwdMovConfig
      IfVeSMSbThdRwRtStFrwdBkwdMovConfig: nonqueued-receiver-com-spec{data-element=IfVeSMSbThdRwRtStFrwdBkwdMovConfig/Val, filter=data-filter-type=ALWAYS, init-value=0}, required-interface=IfVeSMSbThdRwRtStFrwdBkwdMovConfig
      IfVeSMSuPassStBkReclnUpwdDnwdPos: nonqueued-receiver-com-spec{data-element=IfVeSMSuPassStBkReclnUpwdDnwdPos/Val, filter=data-filter-type=ALWAYS, init-value=0}, required-interface=IfVeSMSuPassStBkReclnUpwdDnwdPos
      IfVeSMSuPassStBkReclnUpwdDnwdPosV: nonqueued-receiver-com-spec{data-element=IfVeSMSuPassStBkReclnUpwdDnwdPosV/Val, filter=data-filter-type=ALWAYS, init-value=0}, required-interface=IfVeSMSuPassStBkReclnUpwdDnwdPosV
      IfVeSMSuPassStFldUpwdDnwdPos: nonqueued-receiver-com-spec{data-element=IfVeSMSuPassStFldUpwdDnwdPos/Val, filter=data-filter-type=ALWAYS, init-value=0}, required-interface=IfVeSMSuPassStFldUpwdDnwdPos
      IfVeSMSuPassStFldUpwdDnwdPosV: nonqueued-receiver-com-spec{data-element=IfVeSMSuPassStFldUpwdDnwdPosV/Val, filter=data-filter-type=ALWAYS, init-value=0}, required-interface=IfVeSMSuPassStFldUpwdDnwdPosV
      IfVeSMSuPassStFrwdBkwdPos: nonqueued-receiver-com-spec{data-element=IfVeSMSuPassStFrwdBkwdPos/Val, filter=data-filter-type=ALWAYS, init-value=0}, required-interface=IfVeSMSuPassStFrwdBkwdPos
      IfVeSMSuPassStFrwdBkwdPosV: nonqueued-receiver-com-spec{data-element=IfVeSMSuPassStFrwdBkwdPosV/Val, filter=data-filter-type=ALWAYS, init-value=0}, required-interface=IfVeSMSuPassStFrwdBkwdPosV
      IfVeSMSuSecRwLtStBkReclnUpwdDnwdPos: nonqueued-receiver-com-spec{data-element=IfVeSMSuSecRwLtStBkReclnUpwdDnwdPos/Val, filter=data-filter-type=ALWAYS, init-value=0}, required-interface=IfVeSMSuSecRwLtStBkReclnUpwdDnwdPos
      IfVeSMSuSecRwLtStBkReclnUpwdDnwdPosV: nonqueued-receiver-com-spec{data-element=IfVeSMSuSecRwLtStBkReclnUpwdDnwdPosV/Val, filter=data-filter-type=ALWAYS, init-value=0}, required-interface=IfVeSMSuSecRwLtStBkReclnUpwdDnwdPosV
      IfVeSMSuSecRwLtStFrwdBkwdPos: nonqueued-receiver-com-spec{data-element=IfVeSMSuSecRwLtStFrwdBkwdPos/Val, filter=data-filter-type=ALWAYS, init-value=0}, required-interface=IfVeSMSuSecRwLtStFrwdBkwdPos
      IfVeSMSuSecRwLtStFrwdBkwdPosV: nonqueued-receiver-com-spec{data-element=IfVeSMSuSecRwLtStFrwdBkwdPosV/Val, filter=data-filter-type=ALWAYS, init-value=0}, required-interface=IfVeSMSuSecRwLtStFrwdBkwdPosV
      IfVeSMSuSecRwLtStLgrstOtwdInwdPos: nonqueued-receiver-com-spec{data-element=IfVeSMSuSecRwLtStLgrstOtwdInwdPos/Val, filter=data-filter-type=ALWAYS, init-value=0}, required-interface=IfVeSMSuSecRwLtStLgrstOtwdInwdPos
      IfVeSMSuSecRwLtStLgrstOtwdInwdPosV: nonqueued-receiver-com-spec{data-element=IfVeSMSuSecRwLtStLgrstOtwdInwdPosV/Val, filter=data-filter-type=ALWAYS, init-value=0}, required-interface=IfVeSMSuSecRwLtStLgrstOtwdInwdPosV
      IfVeSMSuSecRwLtStLgrstUpwdDnwdPos: nonqueued-receiver-com-spec{data-element=IfVeSMSuSecRwLtStLgrstUpwdDnwdPos/Val, filter=data-filter-type=ALWAYS, init-value=0}, required-interface=IfVeSMSuSecRwLtStLgrstUpwdDnwdPos
      IfVeSMSuSecRwLtStLgrstUpwdDnwdPosV: nonqueued-receiver-com-spec{data-element=IfVeSMSuSecRwLtStLgrstUpwdDnwdPosV/Val, filter=data-filter-type=ALWAYS, init-value=0}, required-interface=IfVeSMSuSecRwLtStLgrstUpwdDnwdPosV
      IfVeSMSuSecRwLtStZeroPos: nonqueued-receiver-com-spec{data-element=PercPos/Val, filter=data-filter-type=ALWAYS, init-value=0}, required-interface=PercPos
      IfVeSMSuSecRwLtStZeroPosV: nonqueued-receiver-com-spec{data-element=PercPosV/Val, filter=data-filter-type=ALWAYS, init-value=0}, required-interface=PercPosV
      IfVeSMSuSecRwRtStBkReclnUpwdDnwdPos: nonqueued-receiver-com-spec{data-element=IfVeSMSuSecRwRtStBkReclnUpwdDnwdPos/Val, filter=data-filter-type=ALWAYS, init-value=0}, required-interface=IfVeSMSuSecRwRtStBkReclnUpwdDnwdPos
      IfVeSMSuSecRwRtStBkReclnUpwdDnwdPosV: nonqueued-receiver-com-spec{data-element=IfVeSMSuSecRwRtStBkReclnUpwdDnwdPosV/Val, filter=data-filter-type=ALWAYS, init-value=0}, required-interface=IfVeSMSuSecRwRtStBkReclnUpwdDnwdPosV
      IfVeSMSuSecRwRtStFrwdBkwdPos: nonqueued-receiver-com-spec{data-element=PercPos/Val, filter=data-filter-type=ALWAYS, init-value=0}, required-interface=PercPos
      IfVeSMSuSecRwRtStFrwdBkwdPosV: nonqueued-receiver-com-spec{data-element=IfVeSMSuSecRwRtStFrwdBkwdPosV/Val, filter=data-filter-type=ALWAYS, init-value=0}, required-interface=IfVeSMSuSecRwRtStFrwdBkwdPosV
      IfVeSMSuSecRwRtStLgrstOtwdInwdPos: nonqueued-receiver-com-spec{data-element=IfVeSMSuSecRwRtStLgrstOtwdInwdPos/Val, filter=data-filter-type=ALWAYS, init-value=0}, required-interface=IfVeSMSuSecRwRtStLgrstOtwdInwdPos
      IfVeSMSuSecRwRtStLgrstOtwdInwdPosV: nonqueued-receiver-com-spec{data-element=IfVeSMSuSecRwRtStLgrstOtwdInwdPosV/Val, filter=data-filter-type=ALWAYS, init-value=0}, required-interface=IfVeSMSuSecRwRtStLgrstOtwdInwdPosV
      IfVeSMSuSecRwRtStLgrstUpwdDnwdPos: nonqueued-receiver-com-spec{data-element=IfVeSMSuSecRwRtStLgrstUpwdDnwdPos/Val, filter=data-filter-type=ALWAYS, init-value=0}, required-interface=IfVeSMSuSecRwRtStLgrstUpwdDnwdPos
      IfVeSMSuSecRwRtStLgrstUpwdDnwdPosV: nonqueued-receiver-com-spec{data-element=IfVeSMSuSecRwRtStLgrstUpwdDnwdPosV/Val, filter=data-filter-type=ALWAYS, init-value=0}, required-interface=IfVeSMSuSecRwRtStLgrstUpwdDnwdPosV
      IfVeSMSuSecRwRtStZeroPos: nonqueued-receiver-com-spec{data-element=PercPos/Val, filter=data-filter-type=ALWAYS, init-value=0}, required-interface=PercPos
      IfVeSMSuSecRwRtStZeroPosV: nonqueued-receiver-com-spec{data-element=PercPosV/Val, filter=data-filter-type=ALWAYS, init-value=0}, required-interface=PercPosV
      IfVeSMSuThdRwLtStBkReclnUpwdDnwdPos: nonqueued-receiver-com-spec{data-element=IfVeSMSuThdRwLtStBkReclnUpwdDnwdPos/Val, filter=data-filter-type=ALWAYS, init-value=0}, required-interface=IfVeSMSuThdRwLtStBkReclnUpwdDnwdPos
      IfVeSMSuThdRwLtStBkReclnUpwdDnwdPosV: nonqueued-receiver-com-spec{data-element=IfVeSMSuThdRwLtStBkReclnUpwdDnwdPosV/Val, filter=data-filter-type=ALWAYS, init-value=0}, required-interface=IfVeSMSuThdRwLtStBkReclnUpwdDnwdPosV
      IfVeSMSuThdRwLtStCshnFldUpwdDnwdPos: nonqueued-receiver-com-spec{data-element=IfVeSMSuThdRwLtStCshnFldUpwdDnwdPos/Val, filter=data-filter-type=ALWAYS, init-value=0}, required-interface=IfVeSMSuThdRwLtStCshnFldUpwdDnwdPos
      IfVeSMSuThdRwLtStCshnFldUpwdDnwdPosV: nonqueued-receiver-com-spec{data-element=IfVeSMSuThdRwLtStCshnFldUpwdDnwdPosV/Val, filter=data-filter-type=ALWAYS, init-value=0}, required-interface=IfVeSMSuThdRwLtStCshnFldUpwdDnwdPosV
      IfVeSMSuThdRwLtStFrwdBkwdPos: nonqueued-receiver-com-spec{data-element=IfVeSMSuThdRwLtStFrwdBkwdPos/Val, filter=data-filter-type=ALWAYS, init-value=0}, required-interface=IfVeSMSuThdRwLtStFrwdBkwdPos
      IfVeSMSuThdRwLtStFrwdBkwdPosV: nonqueued-receiver-com-spec{data-element=IfVeSMSuThdRwLtStFrwdBkwdPosV/Val, filter=data-filter-type=ALWAYS, init-value=0}, required-interface=IfVeSMSuThdRwLtStFrwdBkwdPosV
      IfVeSMSuThdRwRtStBkReclnUpwdDnwdPos: nonqueued-receiver-com-spec{data-element=IfVeSMSuThdRwRtStBkReclnUpwdDnwdPos/Val, filter=data-filter-type=ALWAYS, init-value=0}, required-interface=IfVeSMSuThdRwRtStBkReclnUpwdDnwdPos
      IfVeSMSuThdRwRtStBkReclnUpwdDnwdPosV: nonqueued-receiver-com-spec{data-element=IfVeSMSuThdRwRtStBkReclnUpwdDnwdPosV/Val, filter=data-filter-type=ALWAYS, init-value=0}, required-interface=IfVeSMSuThdRwRtStBkReclnUpwdDnwdPosV
      IfVeSMSuThdRwRtStCshnFldUpwdDnwdPos: nonqueued-receiver-com-spec{data-element=IfVeSMSuThdRwRtStCshnFldUpwdDnwdPos/Val, filter=data-filter-type=ALWAYS, init-value=0}, required-interface=IfVeSMSuThdRwRtStCshnFldUpwdDnwdPos
      IfVeSMSuThdRwRtStCshnFldUpwdDnwdPosV: nonqueued-receiver-com-spec{data-element=IfVeSMSuThdRwRtStCshnFldUpwdDnwdPosV/Val, filter=data-filter-type=ALWAYS, init-value=0}, required-interface=IfVeSMSuThdRwRtStCshnFldUpwdDnwdPosV
      IfVeSMSuThdRwRtStFrwdBkwdPos: nonqueued-receiver-com-spec{data-element=IfVeSMSuThdRwRStFrwdBkwdPos/Val, filter=data-filter-type=ALWAYS, init-value=0}, required-interface=IfVeSMSuThdRwRStFrwdBkwdPos
      IfVeSMSuThdRwRtStFrwdBkwdPosV: nonqueued-receiver-com-spec{data-element=IfVeSMSuThdRwRtStFrwdBkwdPosV/Val, filter=data-filter-type=ALWAYS, init-value=0}, required-interface=IfVeSMSuThdRwRtStFrwdBkwdPosV
      KeSMSuFirstRwStBackPosDelta: parameter-require-com-spec{init-value=150, parameter=MdPosDelta/Val}, required-interface=MdPosDelta
      KeSMSuFirstRwStCushFoldPosDelta: parameter-require-com-spec{init-value=150, parameter=MdPosDelta/Val}, required-interface=MdPosDelta
      KeSMSuFirstRwStFwdBkwdPosDelta: parameter-require-com-spec{init-value=150, parameter=MdPosDelta/Val}, required-interface=MdPosDelta
      KeSMSuThrdRwCushFoldPosDelta: parameter-require-com-spec{init-value=150, parameter=MdPosDelta/Val}, required-interface=MdPosDelta
      KeSMSwAcsMd30PassStBkReclnUpwdDnwdPos1: parameter-require-com-spec{init-value=0, parameter=Pos/Val}, required-interface=Pos
      KeSMSwAcsMd30PassStBkReclnUpwdDnwdPos1Max: parameter-require-com-spec{init-value=0, parameter=Pos/Val}, required-interface=Pos
      KeSMSwAcsMd30PassStBkReclnUpwdDnwdPos1Min: parameter-require-com-spec{init-value=0, parameter=Pos/Val}, required-interface=Pos
      KeSMSwAcsMd30PassStFldUpwdDnwdPos1: parameter-require-com-spec{init-value=0, parameter=Pos/Val}, required-interface=Pos
      KeSMSwAcsMd30PassStFrwdBkwdPos1: parameter-require-com-spec{init-value=0, parameter=Pos/Val}, required-interface=Pos
      KeSMSwAcsMd30PassStFrwdBkwdPos1Max: parameter-require-com-spec{init-value=0, parameter=Pos/Val}, required-interface=Pos
      KeSMSwAcsMd30PassStFrwdBkwdPos1Min: parameter-require-com-spec{init-value=0, parameter=Pos/Val}, required-interface=Pos
      KeSMSwSeatBkLimitPos: parameter-require-com-spec{init-value=2052, parameter=MdPosDelta/Val}, required-interface=MdPosDelta
      KeSMSwSeatBkLimitPosDelt: parameter-require-com-spec{init-value=120, parameter=MdPosDelta/Val}, required-interface=MdPosDelta
      modestate32: nonqueued-receiver-com-spec{data-element=modestate32/Val, filter=data-filter-type=ALWAYS, init-value=0}, required-interface=modestate32
      StPassCmprtRestMdMemVirtCtrlReqMdadjust: nonqueued-receiver-com-spec{data-element=StPassCmprtRestMdMemVirtCtrlReqMdadjust/Val, filter=data-filter-type=ALWAYS, init-value=0}, required-interface=StPassCmprtRestMdMemVirtCtrlReqMdadjust
    behavior Md61Md62CalibSet_InternalBehavior
      operation invoked event OIT_Md61Md62CalibSet_Cal_Md61Md62CalibSet_Cal: start-on-event=Md61Md62CalibSet_Cal, operation=Md61Md62CalibSet.Cal
      timing event Md61Md62CalibSet_InitEvent: start-on-event=Md61Md62CalibSet_Init, period=0
      runnable Md61Md62CalibSet_Cal
        data-receive-point-by-arguments:
          97 x access:
            REC_EepMd61PassStBkReclnTrgtPos_Val: accessed-variable=EepMd61PassStBkReclnTrgtPos.Val
            REC_EepMd61PassStCshnFldTrgtPos_Val: accessed-variable=EepMd61PassStCshnFldTrgtPos.Val
            REC_EepMd61PassStFwdBkwdTrgtPos_Val: accessed-variable=EepMd61PassStFwdBkwdTrgtPos.Val
            REC_EepMd61SecRwLtStBkReclnTrgtPos_Val: accessed-variable=EepMd61SecRwLtStBkReclnTrgtPos.Val
            REC_EepMd61SecRwLtStCushFrntTrgtPos_Val: accessed-variable=EepMd61SecRwLtStCushFrntTrgtPos.Val
            REC_EepMd61SecRwLtStFwdBkwdTrgtPos_Val: accessed-variable=EepMd61SecRwLtStFwdBkwdTrgtPos.Val
            REC_EepMd61SecRwLtStLgrstInwdOtwdTrgtPos_Val: accessed-variable=EepMd61SecRwLtStLgrstInwdOtwdTrgtPos.Val
            REC_EepMd61SecRwLtStLgrstUpwdDnwdTrgtPos_Val: accessed-variable=EepMd61SecRwLtStLgrstUpwdDnwdTrgtPos.Val
            REC_EepMd61SecRwRtStBkReclnTrgtPos_Val: accessed-variable=EepMd61SecRwRtStBkReclnTrgtPos.Val
            REC_EepMd61SecRwRtStCushFrntTrgtPos_Val: accessed-variable=EepMd61SecRwRtStCushFrntTrgtPos.Val
            REC_EepMd61SecRwRtStFwdBkwdTrgtPos_Val: accessed-variable=EepMd61SecRwRtStFwdBkwdTrgtPos.Val
            REC_EepMd61SecRwRtStLgrstInwdOtwdTrgtPos_Val: accessed-variable=EepMd61SecRwRtStLgrstInwdOtwdTrgtPos.Val
            REC_EepMd61SecRwRtStLgrstUpwdDnwdTrgtPos_Val: accessed-variable=EepMd61SecRwRtStLgrstUpwdDnwdTrgtPos.Val
            REC_EepMd61ThdRwLtStBkReclnTrgtPos_Val: accessed-variable=EepMd61ThdRwLtStBkReclnTrgtPos.Val
            REC_EepMd61ThdRwLtStCshnFldTrgtPos_Val: accessed-variable=EepMd61ThdRwLtStCshnFldTrgtPos.Val
            REC_EepMd61ThdRwLtStFwdBkwdTrgtPos_Val: accessed-variable=EepMd61ThdRwLtStFwdBkwdTrgtPos.Val
            REC_EepMd61ThdRwRtStBkReclnTrgtPos_Val: accessed-variable=EepMd61ThdRwRtStBkReclnTrgtPos.Val
            REC_EepMd61ThdRwRtStCshnFldTrgtPos_Val: accessed-variable=EepMd61ThdRwRtStCshnFldTrgtPos.Val
            REC_EepMd61ThdRwRtStFwdBkwdTrgtPos_Val: accessed-variable=EepMd61ThdRwRtStFwdBkwdTrgtPos.Val
            REC_EepMd62PassStBkReclnTrgtPos_Val: accessed-variable=EepMd62PassStBkReclnTrgtPos.Val
            REC_EepMd62PassStCshnFldTrgtPos_Val: accessed-variable=EepMd62PassStCshnFldTrgtPos.Val
            REC_EepMd62PassStFwdBkwdTrgtPos_Val: accessed-variable=EepMd62PassStFwdBkwdTrgtPos.Val
            REC_EepMd62SecRwLtStBkReclnTrgtPos_Val: accessed-variable=EepMd62SecRwLtStBkReclnTrgtPos.Val
            REC_EepMd62SecRwLtStCushFrntTrgtPos_Val: accessed-variable=EepMd62SecRwLtStCushFrntTrgtPos.Val
            REC_EepMd62SecRwLtStFwdBkwdTrgtPos_Val: accessed-variable=EepMd62SecRwLtStFwdBkwdTrgtPos.Val
            REC_EepMd62SecRwLtStLgrstInwdOtwdTrgtPos_Val: accessed-variable=EepMd62SecRwLtStLgrstInwdOtwdTrgtPos.Val
            REC_EepMd62SecRwLtStLgrstUpwdDnwdTrgtPos_Val: accessed-variable=EepMd62SecRwLtStLgrstUpwdDnwdTrgtPos.Val
            REC_EepMd62SecRwRtStBkReclnTrgtPos_Val: accessed-variable=EepMd62SecRwRtStBkReclnTrgtPos.Val
            REC_EepMd62SecRwRtStCushFrntTrgtPos_Val: accessed-variable=EepMd62SecRwRtStCushFrntTrgtPos.Val
            REC_EepMd62SecRwRtStFwdBkwdTrgtPos_Val: accessed-variable=EepMd62SecRwRtStFwdBkwdTrgtPos.Val
            REC_EepMd62SecRwRtStLgrstInwdOtwdTrgtPos_Val: accessed-variable=EepMd62SecRwRtStLgrstInwdOtwdTrgtPos.Val
            REC_EepMd62SecRwRtStLgrstUpwdDnwdTrgtPos_Val: accessed-variable=EepMd62SecRwRtStLgrstUpwdDnwdTrgtPos.Val
            REC_EepMd62ThdRwLtStBkReclnTrgtPos_Val: accessed-variable=EepMd62ThdRwLtStBkReclnTrgtPos.Val
            REC_EepMd62ThdRwLtStCshnFldTrgtPos_Val: accessed-variable=EepMd62ThdRwLtStCshnFldTrgtPos.Val
            REC_EepMd62ThdRwLtStFwdBkwdTrgtPos_Val: accessed-variable=EepMd62ThdRwLtStFwdBkwdTrgtPos.Val
            REC_EepMd62ThdRwRtStBkReclnTrgtPos_Val: accessed-variable=EepMd62ThdRwRtStBkReclnTrgtPos.Val
            REC_EepMd62ThdRwRtStCshnFldTrgtPos_Val: accessed-variable=EepMd62ThdRwRtStCshnFldTrgtPos.Val
            REC_EepMd62ThdRwRtStFwdBkwdTrgtPos_Val: accessed-variable=EepMd62ThdRwRtStFwdBkwdTrgtPos.Val
            REC_IfVeSMSbPassStBkReclnUpwdDnwdMovConfig_Val: accessed-variable=IfVeSMSbPassStBkReclnUpwdDnwdMovConfig.Val
            REC_IfVeSMSbPassStFldUpwdDnwdMovConfig_Val: accessed-variable=IfVeSMSbPassStFldUpwdDnwdMovConfig.Val
            REC_IfVeSMSbPassStFrwdBkwdMovConfig_Val: accessed-variable=IfVeSMSbPassStFrwdBkwdMovConfig.Val
            REC_IfVeSMSbSecRwLtSLgrstExpdMovConfig_Val: accessed-variable=IfVeSMSbSecRwLtSLgrstExpdMovConfig.Val
            REC_IfVeSMSbSecRwLtStBkReclnUpwdDnwdMovConfig_Val: accessed-variable=IfVeSMSbSecRwLtStBkReclnUpwdDnwdMovConfig.Val
            REC_IfVeSMSbSecRwLtStCshnFrntUpwdDnwdMovConfig_Val: accessed-variable=IfVeSMSbSecRwLtStCshnFrntUpwdDnwdMovConfig.Val
            REC_IfVeSMSbSecRwLtStFrwdBkwdMovConfig_Val: accessed-variable=IfVeSMSbSecRwLtStFrwdBkwdMovConfig.Val
            REC_IfVeSMSbSecRwLtStLgrstUpwdMovConfig_Val: accessed-variable=IfVeSMSbSecRwLtStLgrstUpwdMovConfig.Val
            REC_IfVeSMSbSecRwRtSLgrstExpdMovConfig_Val: accessed-variable=IfVeSMSbSecRwRtSLgrstExpdMovConfig.Val
            REC_IfVeSMSbSecRwRtStBkReclnUpwdDnwdMovConfig_Val: accessed-variable=IfVeSMSbSecRwRtStBkReclnUpwdDnwdMovConfig.Val
            REC_IfVeSMSbSecRwRtStCshnFrntUpwdDnwdMovConfig_Val: accessed-variable=IfVeSMSbSecRwRtStCshnFrntUpwdDnwdMovConfig.Val
            REC_IfVeSMSbSecRwRtStFrwdBkwdMovConfig_Val: accessed-variable=IfVeSMSbSecRwRtStFrwdBkwdMovConfig.Val
            REC_IfVeSMSbSecRwRtStLgrstUpwdMovConfig_Val: accessed-variable=IfVeSMSbSecRwRtStLgrstUpwdMovConfig.Val
            REC_IfVeSMSbThdRwLtStBkReclnUpwdDnwdMovConfig_Val: accessed-variable=IfVeSMSbThdRwLtStBkReclnUpwdDnwdMovConfig.Val
            REC_IfVeSMSbThdRwLtStCshnFldUpwdDnwdMovConfig_Val: accessed-variable=IfVeSMSbThdRwLtStCshnFldUpwdDnwdMovConfig.Val
            REC_IfVeSMSbThdRwLtStFrwdBkwdMovConfig_Val: accessed-variable=IfVeSMSbThdRwLtStFrwdBkwdMovConfig.Val
            REC_IfVeSMSbThdRwRtStBkReclnUpwdDnwdMovConfig_Val: accessed-variable=IfVeSMSbThdRwRtStBkReclnUpwdDnwdMovConfig.Val
            REC_IfVeSMSbThdRwRtStCshnFldUpwdDnwdMovConfig_Val: accessed-variable=IfVeSMSbThdRwRtStCshnFldUpwdDnwdMovConfig.Val
            REC_IfVeSMSbThdRwRtStFrwdBkwdMovConfig_Val: accessed-variable=IfVeSMSbThdRwRtStFrwdBkwdMovConfig.Val
            REC_IfVeSMSuPassStBkReclnUpwdDnwdPos_Val: accessed-variable=IfVeSMSuPassStBkReclnUpwdDnwdPos.Val
            REC_IfVeSMSuPassStBkReclnUpwdDnwdPosV_Val: accessed-variable=IfVeSMSuPassStBkReclnUpwdDnwdPosV.Val
            REC_IfVeSMSuPassStFldUpwdDnwdPos_Val: accessed-variable=IfVeSMSuPassStFldUpwdDnwdPos.Val
            REC_IfVeSMSuPassStFldUpwdDnwdPosV_Val: accessed-variable=IfVeSMSuPassStFldUpwdDnwdPosV.Val
            REC_IfVeSMSuPassStFrwdBkwdPos_Val: accessed-variable=IfVeSMSuPassStFrwdBkwdPos.Val
            REC_IfVeSMSuPassStFrwdBkwdPosV_Val: accessed-variable=IfVeSMSuPassStFrwdBkwdPosV.Val
            REC_IfVeSMSuSecRwLtStBkReclnUpwdDnwdPos_Val: accessed-variable=IfVeSMSuSecRwLtStBkReclnUpwdDnwdPos.Val
            REC_IfVeSMSuSecRwLtStBkReclnUpwdDnwdPosV_Val: accessed-variable=IfVeSMSuSecRwLtStBkReclnUpwdDnwdPosV.Val
            REC_IfVeSMSuSecRwLtStFrwdBkwdPos_Val: accessed-variable=IfVeSMSuSecRwLtStFrwdBkwdPos.Val
            REC_IfVeSMSuSecRwLtStFrwdBkwdPosV_Val: accessed-variable=IfVeSMSuSecRwLtStFrwdBkwdPosV.Val
            REC_IfVeSMSuSecRwLtStLgrstOtwdInwdPos_Val: accessed-variable=IfVeSMSuSecRwLtStLgrstOtwdInwdPos.Val
            REC_IfVeSMSuSecRwLtStLgrstOtwdInwdPosV_Val: accessed-variable=IfVeSMSuSecRwLtStLgrstOtwdInwdPosV.Val
            REC_IfVeSMSuSecRwLtStLgrstUpwdDnwdPos_Val: accessed-variable=IfVeSMSuSecRwLtStLgrstUpwdDnwdPos.Val
            REC_IfVeSMSuSecRwLtStLgrstUpwdDnwdPosV_Val: accessed-variable=IfVeSMSuSecRwLtStLgrstUpwdDnwdPosV.Val
            REC_IfVeSMSuSecRwLtStZeroPos_Val: accessed-variable=IfVeSMSuSecRwLtStZeroPos.Val
            REC_IfVeSMSuSecRwLtStZeroPosV_Val: accessed-variable=IfVeSMSuSecRwLtStZeroPosV.Val
            REC_IfVeSMSuSecRwRtStBkReclnUpwdDnwdPos_Val: accessed-variable=IfVeSMSuSecRwRtStBkReclnUpwdDnwdPos.Val
            REC_IfVeSMSuSecRwRtStBkReclnUpwdDnwdPosV_Val: accessed-variable=IfVeSMSuSecRwRtStBkReclnUpwdDnwdPosV.Val
            REC_IfVeSMSuSecRwRtStFrwdBkwdPos_Val: accessed-variable=IfVeSMSuSecRwRtStFrwdBkwdPos.Val
            REC_IfVeSMSuSecRwRtStFrwdBkwdPosV_Val: accessed-variable=IfVeSMSuSecRwRtStFrwdBkwdPosV.Val
            REC_IfVeSMSuSecRwRtStLgrstOtwdInwdPos_Val: accessed-variable=IfVeSMSuSecRwRtStLgrstOtwdInwdPos.Val
            REC_IfVeSMSuSecRwRtStLgrstOtwdInwdPosV_Val: accessed-variable=IfVeSMSuSecRwRtStLgrstOtwdInwdPosV.Val
            REC_IfVeSMSuSecRwRtStLgrstUpwdDnwdPos_Val: accessed-variable=IfVeSMSuSecRwRtStLgrstUpwdDnwdPos.Val
            REC_IfVeSMSuSecRwRtStLgrstUpwdDnwdPosV_Val: accessed-variable=IfVeSMSuSecRwRtStLgrstUpwdDnwdPosV.Val
            REC_IfVeSMSuSecRwRtStZeroPos_Val: accessed-variable=IfVeSMSuSecRwRtStZeroPos.Val
            REC_IfVeSMSuSecRwRtStZeroPosV_Val: accessed-variable=IfVeSMSuSecRwRtStZeroPosV.Val
            REC_IfVeSMSuThdRwLtStBkReclnUpwdDnwdPos_Val: accessed-variable=IfVeSMSuThdRwLtStBkReclnUpwdDnwdPos.Val
            REC_IfVeSMSuThdRwLtStBkReclnUpwdDnwdPosV_Val: accessed-variable=IfVeSMSuThdRwLtStBkReclnUpwdDnwdPosV.Val
            REC_IfVeSMSuThdRwLtStCshnFldUpwdDnwdPos_Val: accessed-variable=IfVeSMSuThdRwLtStCshnFldUpwdDnwdPos.Val
            REC_IfVeSMSuThdRwLtStCshnFldUpwdDnwdPosV_Val: accessed-variable=IfVeSMSuThdRwLtStCshnFldUpwdDnwdPosV.Val
            REC_IfVeSMSuThdRwLtStFrwdBkwdPos_Val: accessed-variable=IfVeSMSuThdRwLtStFrwdBkwdPos.Val
            REC_IfVeSMSuThdRwLtStFrwdBkwdPosV_Val: accessed-variable=IfVeSMSuThdRwLtStFrwdBkwdPosV.Val
            REC_IfVeSMSuThdRwRtStBkReclnUpwdDnwdPos_Val: accessed-variable=IfVeSMSuThdRwRtStBkReclnUpwdDnwdPos.Val
            REC_IfVeSMSuThdRwRtStBkReclnUpwdDnwdPosV_Val: accessed-variable=IfVeSMSuThdRwRtStBkReclnUpwdDnwdPosV.Val
            REC_IfVeSMSuThdRwRtStCshnFldUpwdDnwdPos_Val: accessed-variable=IfVeSMSuThdRwRtStCshnFldUpwdDnwdPos.Val
            REC_IfVeSMSuThdRwRtStCshnFldUpwdDnwdPosV_Val: accessed-variable=IfVeSMSuThdRwRtStCshnFldUpwdDnwdPosV.Val
            REC_IfVeSMSuThdRwRtStFrwdBkwdPos_Val: accessed-variable=IfVeSMSuThdRwRtStFrwdBkwdPos.Val
            REC_IfVeSMSuThdRwRtStFrwdBkwdPosV_Val: accessed-variable=IfVeSMSuThdRwRtStFrwdBkwdPosV.Val
            REC_modestate32_Val: accessed-variable=modestate32.Val
            REC_StPassCmprtRestMdMemVirtCtrlReqMdadjust_Val: accessed-variable=StPassCmprtRestMdMemVirtCtrlReqMdadjust.Val
        data-send-points:
          98 x access:
            SEND_EepMd61PassStBkReclnTrgtPos_S_Val: accessed-variable=EepMd61PassStBkReclnTrgtPos_S.Val
            SEND_EepMd61PassStCshnFldTrgtPos_S_Val: accessed-variable=EepMd61PassStCshnFldTrgtPos_S.Val
            SEND_EepMd61PassStFwdBkwdTrgtPos_S_Val: accessed-variable=EepMd61PassStFwdBkwdTrgtPos_S.Val
            SEND_EepMd61SecRwLtStBkReclnTrgtPos_S_Val: accessed-variable=EepMd61SecRwLtStBkReclnTrgtPos_S.Val
            SEND_EepMd61SecRwLtStCushFrntTrgtPos_S_Val: accessed-variable=EepMd61SecRwLtStCushFrntTrgtPos_S.Val
            SEND_EepMd61SecRwLtStFwdBkwdTrgtPos_S_Val: accessed-variable=EepMd61SecRwLtStFwdBkwdTrgtPos_S.Val
            SEND_EepMd61SecRwLtStLgrstInwdOtwdTrgtPos_S_Val: accessed-variable=EepMd61SecRwLtStLgrstInwdOtwdTrgtPos_S.Val
            SEND_EepMd61SecRwLtStLgrstUpwdDnwdTrgtPos_S_Val: accessed-variable=EepMd61SecRwLtStLgrstUpwdDnwdTrgtPos_S.Val
            SEND_EepMd61SecRwRtStBkReclnTrgtPos_S_Val: accessed-variable=EepMd61SecRwRtStBkReclnTrgtPos_S.Val
            SEND_EepMd61SecRwRtStCushFrntTrgtPos_S_Val: accessed-variable=EepMd61SecRwRtStCushFrntTrgtPos_S.Val
            SEND_EepMd61SecRwRtStFwdBkwdTrgtPos_S_Val: accessed-variable=EepMd61SecRwRtStFwdBkwdTrgtPos_S.Val
            SEND_EepMd61SecRwRtStLgrstInwdOtwdTrgtPos_S_Val: accessed-variable=EepMd61SecRwRtStLgrstInwdOtwdTrgtPos_S.Val
            SEND_EepMd61SecRwRtStLgrstUpwdDnwdTrgtPos_S_Val: accessed-variable=EepMd61SecRwRtStLgrstUpwdDnwdTrgtPos_S.Val
            SEND_EepMd61ThdRwLtStBkReclnTrgtPos_S_Val: accessed-variable=EepMd61ThdRwLtStBkReclnTrgtPos_S.Val
            SEND_EepMd61ThdRwLtStCshnFldTrgtPos_S_Val: accessed-variable=EepMd61ThdRwLtStCshnFldTrgtPos_S.Val
            SEND_EepMd61ThdRwLtStFwdBkwdTrgtPos_S_Val: accessed-variable=EepMd61ThdRwLtStFwdBkwdTrgtPos_S.Val
            SEND_EepMd61ThdRwRtStBkReclnTrgtPos_S_Val: accessed-variable=EepMd61ThdRwRtStBkReclnTrgtPos_S.Val
            SEND_EepMd61ThdRwRtStCshnFldTrgtPos_S_Val: accessed-variable=EepMd61ThdRwRtStCshnFldTrgtPos_S.Val
            SEND_EepMd61ThdRwRtStFwdBkwdTrgtPos_S_Val: accessed-variable=EepMd61ThdRwRtStFwdBkwdTrgtPos_S.Val
            SEND_EepMd62PassStBkReclnTrgtPos_S_Val: accessed-variable=EepMd62PassStBkReclnTrgtPos_S.Val
            SEND_EepMd62PassStCshnFldTrgtPos_S_Val: accessed-variable=EepMd62PassStCshnFldTrgtPos_S.Val
            SEND_EepMd62PassStFwdBkwdTrgtPos_S_Val: accessed-variable=EepMd62PassStFwdBkwdTrgtPos_S.Val
            SEND_EepMd62SecRwLtStBkReclnTrgtPos_S_Val: accessed-variable=EepMd62SecRwLtStBkReclnTrgtPos_S.Val
            SEND_EepMd62SecRwLtStCushFrntTrgtPos_S_Val: accessed-variable=EepMd62SecRwLtStCushFrntTrgtPos_S.Val
            SEND_EepMd62SecRwLtStFwdBkwdTrgtPos_S_Val: accessed-variable=EepMd62SecRwLtStFwdBkwdTrgtPos_S.Val
            SEND_EepMd62SecRwLtStLgrstInwdOtwdTrgtPos_S_Val: accessed-variable=EepMd62SecRwLtStLgrstInwdOtwdTrgtPos_S.Val
            SEND_EepMd62SecRwLtStLgrstUpwdDnwdTrgtPos_S_Val: accessed-variable=EepMd62SecRwLtStLgrstUpwdDnwdTrgtPos_S.Val
            SEND_EepMd62SecRwRtStBkReclnTrgtPos_S_Val: accessed-variable=EepMd62SecRwRtStBkReclnTrgtPos_S.Val
            SEND_EepMd62SecRwRtStCushFrntTrgtPos_S_Val: accessed-variable=EepMd62SecRwRtStCushFrntTrgtPos_S.Val
            SEND_EepMd62SecRwRtStFwdBkwdTrgtPos_S_Val: accessed-variable=EepMd62SecRwRtStFwdBkwdTrgtPos_S.Val
            SEND_EepMd62SecRwRtStLgrstInwdOtwdTrgtPos_S_Val: accessed-variable=EepMd62SecRwRtStLgrstInwdOtwdTrgtPos_S.Val
            SEND_EepMd62SecRwRtStLgrstUpwdDnwdTrgtPos_S_Val: accessed-variable=EepMd62SecRwRtStLgrstUpwdDnwdTrgtPos_S.Val
            SEND_EepMd62ThdRwLtStBkReclnTrgtPos_S_Val: accessed-variable=EepMd62ThdRwLtStBkReclnTrgtPos_S.Val
            SEND_EepMd62ThdRwLtStCshnFldTrgtPos_S_Val: accessed-variable=EepMd62ThdRwLtStCshnFldTrgtPos_S.Val
            SEND_EepMd62ThdRwLtStFwdBkwdTrgtPos_S_Val: accessed-variable=EepMd62ThdRwLtStFwdBkwdTrgtPos_S.Val
            SEND_EepMd62ThdRwRtStBkReclnTrgtPos_S_Val: accessed-variable=EepMd62ThdRwRtStBkReclnTrgtPos_S.Val
            SEND_EepMd62ThdRwRtStCshnFldTrgtPos_S_Val: accessed-variable=EepMd62ThdRwRtStCshnFldTrgtPos_S.Val
            SEND_EepMd62ThdRwRtStFwdBkwdTrgtPos_S_Val: accessed-variable=EepMd62ThdRwRtStFwdBkwdTrgtPos_S.Val
            SEND_Md61MemReq_Val: accessed-variable=Md61MemReq.Val
            SEND_Md61NotMem_Val: accessed-variable=Md61NotMem.Val
            SEND_Md61PassStBkReclnTrgtPos_Val: accessed-variable=Md61PassStBkReclnTrgtPos.Val
            SEND_Md61PassStBkReclnUpwdDnwdTrgtPosCalib_TrgtPosArray: accessed-variable=Md61PassStBkReclnUpwdDnwdTrgtPosCalib.TrgtPosArray
            SEND_Md61PassStCshnFldTrgtPosCalib_TrgtPosArray: accessed-variable=Md61PassStCshnFldTrgtPosCalib.TrgtPosArray
            SEND_Md61PassStFwdBkwdTrgtPosCalib_TrgtPosArray: accessed-variable=Md61PassStFwdBkwdTrgtPosCalib.TrgtPosArray
            SEND_Md61PassStNeedFldOpn_Val: accessed-variable=Md61PassStNeedFldOpn.Val
            SEND_Md61PassStTrgtIsFld_Val: accessed-variable=Md61PassStTrgtIsFld.Val
            SEND_Md61SecRwLtStBkReclnTrgtPosCalib_TrgtPosArray: accessed-variable=Md61SecRwLtStBkReclnTrgtPosCalib.TrgtPosArray
            SEND_Md61SecRwLtStCushFrntTrgtPosCalib_TrgtPosArray: accessed-variable=Md61SecRwLtStCushFrntTrgtPosCalib.TrgtPosArray
            SEND_Md61SecRwLtStFwdBkwdCalib_TrgtPosArray: accessed-variable=Md61SecRwLtStFwdBkwdCalib.TrgtPosArray
            SEND_Md61SecRwLtStLgrstInwdOtwdTrgtPosCalib_TrgtPosArray: accessed-variable=Md61SecRwLtStLgrstInwdOtwdTrgtPosCalib.TrgtPosArray
            SEND_Md61SecRwLtStLgrstUpwdDnwdTrgtPosCalib_TrgtPosArray: accessed-variable=Md61SecRwLtStLgrstUpwdDnwdTrgtPosCalib.TrgtPosArray
            SEND_Md61SecRwRtStBkReclnTrgtPosCalib_TrgtPosArray: accessed-variable=Md61SecRwRtStBkReclnTrgtPosCalib.TrgtPosArray
            SEND_Md61SecRwRtStCushFrntTrgtPosCalib_TrgtPosArray: accessed-variable=Md61SecRwRtStCushFrntTrgtPosCalib.TrgtPosArray
            SEND_Md61SecRwRtStFwdBkwdCalib_TrgtPosArray: accessed-variable=Md61SecRwRtStFwdBkwdCalib.TrgtPosArray
            SEND_Md61SecRwRtStLgrstInwdOtwdTrgtPosCalib_TrgtPosArray: accessed-variable=Md61SecRwRtStLgrstInwdOtwdTrgtPosCalib.TrgtPosArray
            SEND_Md61SecRwRtStLgrstUpwdDnwdTrgtPosCalib_TrgtPosArray: accessed-variable=Md61SecRwRtStLgrstUpwdDnwdTrgtPosCalib.TrgtPosArray
            SEND_Md61ThdRwLtStBkReclnUpwdDnwdTrgtPosCalib_TrgtPosArray: accessed-variable=Md61ThdRwLtStBkReclnUpwdDnwdTrgtPosCalib.TrgtPosArray
            SEND_Md61ThdRwLtStCshnFldUpwdDnwdTrgtPos_Val: accessed-variable=Md61ThdRwLtStCshnFldUpwdDnwdTrgtPos.Val
            SEND_Md61ThdRwLtStCshnFldUpwdDnwdTrgtPosCalib_TrgtPosArray: accessed-variable=Md61ThdRwLtStCshnFldUpwdDnwdTrgtPosCalib.TrgtPosArray
            SEND_Md61ThdRwLtStFrwdBkwdPosTrgtPosCalib_TrgtPosArray: accessed-variable=Md61ThdRwLtStFrwdBkwdPosTrgtPosCalib.TrgtPosArray
            SEND_Md61ThdRwLtStNeedFldOpn_Val: accessed-variable=Md61ThdRwLtStNeedFldOpn.Val
            SEND_Md61ThdRwLtStTrgtIsFld_Val: accessed-variable=Md61ThdRwLtStTrgtIsFld.Val
            SEND_Md61ThdRwRtStBkReclnUpwdDnwdTrgtPosCalib_TrgtPosArray: accessed-variable=Md61ThdRwRtStBkReclnUpwdDnwdTrgtPosCalib.TrgtPosArray
            SEND_Md61ThdRwRtStCshnFldUpwdDnwdTrgtPos_Val: accessed-variable=Md61ThdRwRtStCshnFldUpwdDnwdTrgtPos.Val
            SEND_Md61ThdRwRtStCshnFldUpwdDnwdTrgtPosCalib_TrgtPosArray: accessed-variable=Md61ThdRwRtStCshnFldUpwdDnwdTrgtPosCalib.TrgtPosArray
            SEND_Md61ThdRwRtStFrwdBkwdPosTrgtPosCalib_TrgtPosArray: accessed-variable=Md61ThdRwRtStFrwdBkwdPosTrgtPosCalib.TrgtPosArray
            SEND_Md61ThdRwRtStNeedFldOpn_Val: accessed-variable=Md61ThdRwRtStNeedFldOpn.Val
            SEND_Md61ThdRwRtStTrgtIsFld_Val: accessed-variable=Md61ThdRwRtStTrgtIsFld.Val
            SEND_Md62MemReq_Val: accessed-variable=Md62MemReq.Val
            SEND_Md62NotMem_Val: accessed-variable=Md62NotMem.Val
            SEND_Md62PassStBkReclnTrgtPos_Val: accessed-variable=Md62PassStBkReclnTrgtPos.Val
            SEND_Md62PassStBkReclnTrgtPosCalib_TrgtPosArray: accessed-variable=Md62PassStBkReclnTrgtPosCalib.TrgtPosArray
            SEND_Md62PassStCshnFldTrgtPosCalib_TrgtPosArray: accessed-variable=Md62PassStCshnFldTrgtPosCalib.TrgtPosArray
            SEND_Md62PassStFwdBkwdTrgtPosCalib_TrgtPosArray: accessed-variable=Md62PassStFwdBkwdTrgtPosCalib.TrgtPosArray
            SEND_Md62PassStNeedFldOpn_Val: accessed-variable=Md62PassStNeedFldOpn.Val
            SEND_Md62PassStTrgtIsFld_Val: accessed-variable=Md62PassStTrgtIsFld.Val
            SEND_Md62SecRwLtStBkReclnTrgtPosCalib_TrgtPosArray: accessed-variable=Md62SecRwLtStBkReclnTrgtPosCalib.TrgtPosArray
            SEND_Md62SecRwLtStCushFrntTrgtPosCalib_TrgtPosArray: accessed-variable=Md62SecRwLtStCushFrntTrgtPosCalib.TrgtPosArray
            SEND_Md62SecRwLtStFwdBkwdCalib_TrgtPosArray: accessed-variable=Md62SecRwLtStFwdBkwdCalib.TrgtPosArray
            SEND_Md62SecRwLtStLgrstInwdOtwdTrgtPosCalib_TrgtPosArray: accessed-variable=Md62SecRwLtStLgrstInwdOtwdTrgtPosCalib.TrgtPosArray
            SEND_Md62SecRwLtStLgrstUpwdDnwdTrgtPosCalib_TrgtPosArray: accessed-variable=Md62SecRwLtStLgrstUpwdDnwdTrgtPosCalib.TrgtPosArray
            SEND_Md62SecRwRtStBkReclnTrgtPosCalib_TrgtPosArray: accessed-variable=Md62SecRwRtStBkReclnTrgtPosCalib.TrgtPosArray
            SEND_Md62SecRwRtStCushFrntTrgtPosCalib_TrgtPosArray: accessed-variable=Md62SecRwRtStCushFrntTrgtPosCalib.TrgtPosArray
            SEND_Md62SecRwRtStFwdBkwdCalib_TrgtPosArray: accessed-variable=Md62SecRwRtStFwdBkwdCalib.TrgtPosArray
            SEND_Md62SecRwRtStLgrstInwdOtwdTrgtPosCalib_TrgtPosArray: accessed-variable=Md62SecRwRtStLgrstInwdOtwdTrgtPosCalib.TrgtPosArray
            SEND_Md62SecRwRtStLgrstUpwdDnwdTrgtPosCalib_TrgtPosArray: accessed-variable=Md62SecRwRtStLgrstUpwdDnwdTrgtPosCalib.TrgtPosArray
            SEND_Md62ThdRwLtStBkReclnUpwdDnwdTrgtPosCalib_TrgtPosArray: accessed-variable=Md62ThdRwLtStBkReclnUpwdDnwdTrgtPosCalib.TrgtPosArray
            SEND_Md62ThdRwLtStCshnFldUpwdDnwdTrgtPos_Val: accessed-variable=Md62ThdRwLtStCshnFldUpwdDnwdTrgtPos.Val
            SEND_Md62ThdRwLtStCshnFldUpwdDnwdTrgtPosCalib_TrgtPosArray: accessed-variable=Md62ThdRwLtStCshnFldUpwdDnwdTrgtPosCalib.TrgtPosArray
            SEND_Md62ThdRwLtStFrwdBkwdPosTrgtPosCalib_TrgtPosArray: accessed-variable=Md62ThdRwLtStFrwdBkwdPosTrgtPosCalib.TrgtPosArray
            SEND_Md62ThdRwLtStNeedFldOpn_Val: accessed-variable=Md62ThdRwLtStNeedFldOpn.Val
            SEND_Md62ThdRwLtStTrgtIsFld_Val: accessed-variable=Md62ThdRwLtStTrgtIsFld.Val
            SEND_Md62ThdRwRtStBkReclnUpwdDnwdTrgtPosCalib_TrgtPosArray: accessed-variable=Md62ThdRwRtStBkReclnUpwdDnwdTrgtPosCalib.TrgtPosArray
            SEND_Md62ThdRwRtStCshnFldUpwdDnwdTrgtPos_Val: accessed-variable=Md62ThdRwRtStCshnFldUpwdDnwdTrgtPos.Val
            SEND_Md62ThdRwRtStCshnFldUpwdDnwdTrgtPosCalib_TrgtPosArray: accessed-variable=Md62ThdRwRtStCshnFldUpwdDnwdTrgtPosCalib.TrgtPosArray
            SEND_Md62ThdRwRtStFrwdBkwdPosTrgtPosCalib_TrgtPosArray: accessed-variable=Md62ThdRwRtStFrwdBkwdPosTrgtPosCalib.TrgtPosArray
            SEND_Md62ThdRwRtStNeedFldOpn_Val: accessed-variable=Md62ThdRwRtStNeedFldOpn.Val
            SEND_Md62ThdRwRtStTrgtIsFld_Val: accessed-variable=Md62ThdRwRtStTrgtIsFld.Val
        13 x parameter access:
          PA_KeSMSuFirstRwStBackPosDelta_Val: accessed-parameter=KeSMSuFirstRwStBackPosDelta.Val
          PA_KeSMSuFirstRwStCushFoldPosDelta_Val: accessed-parameter=KeSMSuFirstRwStCushFoldPosDelta.Val
          PA_KeSMSuFirstRwStFwdBkwdPosDelta_Val: accessed-parameter=KeSMSuFirstRwStFwdBkwdPosDelta.Val
          PA_KeSMSuThrdRwCushFoldPosDelta_Val: accessed-parameter=KeSMSuThrdRwCushFoldPosDelta.Val
          PA_KeSMSwAcsMd30PassStBkReclnUpwdDnwdPos1_Val: accessed-parameter=KeSMSwAcsMd30PassStBkReclnUpwdDnwdPos1.Val
          PA_KeSMSwAcsMd30PassStBkReclnUpwdDnwdPos1Max_Val: accessed-parameter=KeSMSwAcsMd30PassStBkReclnUpwdDnwdPos1Max.Val
          PA_KeSMSwAcsMd30PassStBkReclnUpwdDnwdPos1Min_Val: accessed-parameter=KeSMSwAcsMd30PassStBkReclnUpwdDnwdPos1Min.Val
          PA_KeSMSwAcsMd30PassStFldUpwdDnwdPos1_Val: accessed-parameter=KeSMSwAcsMd30PassStFldUpwdDnwdPos1.Val
          PA_KeSMSwAcsMd30PassStFrwdBkwdPos1_Val: accessed-parameter=KeSMSwAcsMd30PassStFrwdBkwdPos1.Val
          PA_KeSMSwAcsMd30PassStFrwdBkwdPos1Max_Val: accessed-parameter=KeSMSwAcsMd30PassStFrwdBkwdPos1Max.Val
          PA_KeSMSwAcsMd30PassStFrwdBkwdPos1Min_Val: accessed-parameter=KeSMSwAcsMd30PassStFrwdBkwdPos1Min.Val
          PA_KeSMSwSeatBkLimitPos_Val: accessed-parameter=KeSMSwSeatBkLimitPos.Val
          PA_KeSMSwSeatBkLimitPosDelt_Val: accessed-parameter=KeSMSwSeatBkLimitPosDelt.Val
      runnable Md61Md62CalibSet_Init
        13 x parameter access:
          PA_KeSMSuFirstRwStBackPosDelta_Val: accessed-parameter=KeSMSuFirstRwStBackPosDelta.Val
          PA_KeSMSuFirstRwStCushFoldPosDelta_Val: accessed-parameter=KeSMSuFirstRwStCushFoldPosDelta.Val
          PA_KeSMSuFirstRwStFwdBkwdPosDelta_Val: accessed-parameter=KeSMSuFirstRwStFwdBkwdPosDelta.Val
          PA_KeSMSuThrdRwCushFoldPosDelta_Val: accessed-parameter=KeSMSuThrdRwCushFoldPosDelta.Val
          PA_KeSMSwAcsMd30PassStBkReclnUpwdDnwdPos1_Val: accessed-parameter=KeSMSwAcsMd30PassStBkReclnUpwdDnwdPos1.Val
          PA_KeSMSwAcsMd30PassStBkReclnUpwdDnwdPos1Max_Val: accessed-parameter=KeSMSwAcsMd30PassStBkReclnUpwdDnwdPos1Max.Val
          PA_KeSMSwAcsMd30PassStBkReclnUpwdDnwdPos1Min_Val: accessed-parameter=KeSMSwAcsMd30PassStBkReclnUpwdDnwdPos1Min.Val
          PA_KeSMSwAcsMd30PassStFldUpwdDnwdPos1_Val: accessed-parameter=KeSMSwAcsMd30PassStFldUpwdDnwdPos1.Val
          PA_KeSMSwAcsMd30PassStFrwdBkwdPos1_Val: accessed-parameter=KeSMSwAcsMd30PassStFrwdBkwdPos1.Val
          PA_KeSMSwAcsMd30PassStFrwdBkwdPos1Max_Val: accessed-parameter=KeSMSwAcsMd30PassStFrwdBkwdPos1Max.Val
          PA_KeSMSwAcsMd30PassStFrwdBkwdPos1Min_Val: accessed-parameter=KeSMSwAcsMd30PassStFrwdBkwdPos1Min.Val
          PA_KeSMSwSeatBkLimitPos_Val: accessed-parameter=KeSMSwSeatBkLimitPos.Val
          PA_KeSMSwSeatBkLimitPosDelt_Val: accessed-parameter=KeSMSwSeatBkLimitPosDelt.Val
  swc implementation Md61Md62CalibSet_Implementation: behavior=Md61Md62CalibSet_InternalBehavior
    code-descriptors:
      code Default: artifact-descriptors=autosar-engineering-object={short-label=Default, category=SWSRC}
package /PATAC/MSM/ModeAdjust/CalPortInterface
  parameter interface MdPosDelta
    parameter data prototype Val: sw-calibration-access=READ-WRITE, type=UInt16
  parameter interface Pos
    parameter data prototype Val: sw-calibration-access=READ-WRITE, type=UInt16
package /PATAC/MSM/ModeAdjust/DataType
  impl type TrgtPosCalibArray: category=ARRAY, sw-calibration-access=READ-ONLY, type-emitter=RTE  # 0:pos 1:max 2:min
    element Element: array-size=3, array-size-semantics=FIXED-SIZE, implementation-data-type=UInt16, invalid-value=0
package /PATAC/MSM/ModeAdjust/Interfaces
  17 x sender receiver interface:
    IfVeSMSuPassStBkReclnUpwdDnwdPosV: invalidation-policy{data-element=IfVeSMSuPassStBkReclnUpwdDnwdPosV/Val, handle-invalid=DONT-INVALIDATE}
      data Val: type=Boolean
    IfVeSMSuPassStFldUpwdDnwdPosV: invalidation-policy{data-element=IfVeSMSuPassStFldUpwdDnwdPosV/Val, handle-invalid=DONT-INVALIDATE}
      data Val: type=Boolean
    IfVeSMSuPassStFrwdBkwdPosV: invalidation-policy{data-element=IfVeSMSuPassStFrwdBkwdPosV/Val, handle-invalid=DONT-INVALIDATE}
      data Val: type=Boolean
    IfVeSMSuSecRwLtStBkReclnUpwdDnwdPosV: invalidation-policy{data-element=IfVeSMSuSecRwLtStBkReclnUpwdDnwdPosV/Val, handle-invalid=DONT-INVALIDATE}
      data Val: type=Boolean
    IfVeSMSuSecRwLtStFrwdBkwdPosV: invalidation-policy{data-element=IfVeSMSuSecRwLtStFrwdBkwdPosV/Val, handle-invalid=DONT-INVALIDATE}
      data Val: type=Boolean
    IfVeSMSuSecRwLtStLgrstUpwdDnwdPosV: invalidation-policy{data-element=IfVeSMSuSecRwLtStLgrstUpwdDnwdPosV/Val, handle-invalid=DONT-INVALIDATE}
      data Val: type=Boolean
    IfVeSMSuSecRwRtStBkReclnUpwdDnwdPosV: invalidation-policy{data-element=IfVeSMSuSecRwRtStBkReclnUpwdDnwdPosV/Val, handle-invalid=DONT-INVALIDATE}
      data Val: type=Boolean
    IfVeSMSuSecRwRtStFrwdBkwdPosV: invalidation-policy{data-element=IfVeSMSuSecRwRtStFrwdBkwdPosV/Val, handle-invalid=DONT-INVALIDATE}
      data Val: type=Boolean
    IfVeSMSuSecRwRtStLgrstUpwdDnwdPosV: invalidation-policy{data-element=IfVeSMSuSecRwRtStLgrstUpwdDnwdPosV/Val, handle-invalid=DONT-INVALIDATE}
      data Val: type=Boolean
    IfVeSMSuThdRwLtStBkReclnUpwdDnwdPosV: invalidation-policy{data-element=IfVeSMSuThdRwLtStBkReclnUpwdDnwdPosV/Val, handle-invalid=DONT-INVALIDATE}
      data Val: type=Boolean
    IfVeSMSuThdRwLtStCshnFldUpwdDnwdPos: invalidation-policy{data-element=IfVeSMSuThdRwLtStCshnFldUpwdDnwdPos/Val, handle-invalid=DONT-INVALIDATE}
      data Val: type=UInt16
    IfVeSMSuThdRwLtStCshnFldUpwdDnwdPosV: invalidation-policy{data-element=IfVeSMSuThdRwLtStCshnFldUpwdDnwdPosV/Val, handle-invalid=DONT-INVALIDATE}
      data Val: type=Boolean
    IfVeSMSuThdRwLtStFrwdBkwdPosV: invalidation-policy{data-element=IfVeSMSuThdRwLtStFrwdBkwdPosV/Val, handle-invalid=DONT-INVALIDATE}
      data Val: type=Boolean
    IfVeSMSuThdRwRtStBkReclnUpwdDnwdPosV: invalidation-policy{data-element=IfVeSMSuThdRwRtStBkReclnUpwdDnwdPosV/Val, handle-invalid=DONT-INVALIDATE}
      data Val: type=Boolean
    IfVeSMSuThdRwRtStCshnFldUpwdDnwdPos: invalidation-policy{data-element=IfVeSMSuThdRwRtStCshnFldUpwdDnwdPos/Val, handle-invalid=DONT-INVALIDATE}
      data Val: type=UInt16
    IfVeSMSuThdRwRtStCshnFldUpwdDnwdPosV: invalidation-policy{data-element=IfVeSMSuThdRwRtStCshnFldUpwdDnwdPosV/Val, handle-invalid=DONT-INVALIDATE}
      data Val: type=Boolean
    IfVeSMSuThdRwRtStFrwdBkwdPosV: invalidation-policy{data-element=IfVeSMSuThdRwRtStFrwdBkwdPosV/Val, handle-invalid=DONT-INVALIDATE}
      data Val: type=Boolean
package /PATAC/MSM/ModeAdjust/PortInterface
  client server interface Md61Md62CalibSet
    operation Cal
  86 x sender receiver interface:
    EepMd61PassStBkReclnTrgtPos: invalidation-policy{data-element=EepMd61PassStBkReclnTrgtPos/Val, handle-invalid=DONT-INVALIDATE}
      data Val: type=UInt16
    EepMd61PassStBkReclnTrgtPos_S: invalidation-policy{data-element=EepMd61PassStBkReclnTrgtPos_S/Val, handle-invalid=DONT-INVALIDATE}
      data Val: type=UInt16
    EepMd61PassStCshnFldTrgtPos: invalidation-policy{data-element=EepMd61PassStCshnFldTrgtPos/Val, handle-invalid=DONT-INVALIDATE}
      data Val: type=UInt16
    EepMd61PassStCshnFldTrgtPos_S: invalidation-policy{data-element=EepMd61PassStCshnFldTrgtPos_S/Val, handle-invalid=DONT-INVALIDATE}
      data Val: type=UInt16
    EepMd61PassStFwdBkwdTrgtPos: invalidation-policy{data-element=EepMd61PassStFwdBkwdTrgtPos/Val, handle-invalid=DONT-INVALIDATE}
      data Val: type=UInt16
    EepMd61PassStFwdBkwdTrgtPos_S: invalidation-policy{data-element=EepMd61PassStFwdBkwdTrgtPos_S/Val, handle-invalid=DONT-INVALIDATE}
      data Val: type=UInt16
    EepMd61SecRwLtStBkReclnTrgtPos: invalidation-policy{data-element=EepMd61SecRwLtStBkReclnTrgtPos/Val, handle-invalid=DONT-INVALIDATE}
      data Val: type=UInt16
    EepMd61SecRwLtStBkReclnTrgtPos_S: invalidation-policy{data-element=EepMd61SecRwLtStBkReclnTrgtPos_S/Val, handle-invalid=DONT-INVALIDATE}
      data Val: type=UInt16
    EepMd61SecRwLtStCushFrntTrgtPos: invalidation-policy{data-element=EepMd61SecRwLtStCushFrntTrgtPos/Val, handle-invalid=DONT-INVALIDATE}
      data Val: type=UInt16
    EepMd61SecRwLtStCushFrntTrgtPos_S: invalidation-policy{data-element=EepMd61SecRwLtStCushFrntTrgtPos_S/Val, handle-invalid=DONT-INVALIDATE}
      data Val: type=UInt16
    EepMd61SecRwLtStFwdBkwdTrgtPos: invalidation-policy{data-element=EepMd61SecRwLtStFwdBkwdTrgtPos/Val, handle-invalid=DONT-INVALIDATE}
      data Val: type=UInt16
    EepMd61SecRwLtStFwdBkwdTrgtPos_S: invalidation-policy{data-element=EepMd61SecRwLtStFwdBkwdTrgtPos_S/Val, handle-invalid=DONT-INVALIDATE}
      data Val: type=UInt16
    EepMd61SecRwLtStLgrstInwdOtwdTrgtPos: invalidation-policy{data-element=EepMd61SecRwLtStLgrstInwdOtwdTrgtPos/Val, handle-invalid=DONT-INVALIDATE}
      data Val: type=UInt16
    EepMd61SecRwLtStLgrstInwdOtwdTrgtPos_S: invalidation-policy{data-element=EepMd61SecRwLtStLgrstInwdOtwdTrgtPos_S/Val, handle-invalid=DONT-INVALIDATE}
      data Val: type=UInt16
    EepMd61SecRwLtStLgrstUpwdDnwdTrgtPos: invalidation-policy{data-element=EepMd61SecRwLtStLgrstUpwdDnwdTrgtPos/Val, handle-invalid=DONT-INVALIDATE}
      data Val: type=UInt16
    EepMd61SecRwLtStLgrstUpwdDnwdTrgtPos_S: invalidation-policy{data-element=EepMd61SecRwLtStLgrstUpwdDnwdTrgtPos_S/Val, handle-invalid=DONT-INVALIDATE}
      data Val: type=UInt16
    EepMd61SecRwRtStBkReclnTrgtPos: invalidation-policy{data-element=EepMd61SecRwRtStBkReclnTrgtPos/Val, handle-invalid=DONT-INVALIDATE}
      data Val: type=UInt16
    EepMd61SecRwRtStBkReclnTrgtPos_S: invalidation-policy{data-element=EepMd61SecRwRtStBkReclnTrgtPos_S/Val, handle-invalid=DONT-INVALIDATE}
      data Val: type=UInt16
    EepMd61SecRwRtStCushFrntTrgtPos: invalidation-policy{data-element=EepMd61SecRwRtStCushFrntTrgtPos/Val, handle-invalid=DONT-INVALIDATE}
      data Val: type=UInt16
    EepMd61SecRwRtStCushFrntTrgtPos_S: invalidation-policy{data-element=EepMd61SecRwRtStCushFrntTrgtPos_S/Val, handle-invalid=DONT-INVALIDATE}
      data Val: type=UInt16
    EepMd61SecRwRtStFwdBkwdTrgtPos: invalidation-policy{data-element=EepMd61SecRwRtStFwdBkwdTrgtPos/Val, handle-invalid=DONT-INVALIDATE}
      data Val: type=UInt16
    EepMd61SecRwRtStFwdBkwdTrgtPos_S: invalidation-policy{data-element=EepMd61SecRwRtStFwdBkwdTrgtPos_S/Val, handle-invalid=DONT-INVALIDATE}
      data Val: type=UInt16
    EepMd61SecRwRtStLgrstInwdOtwdTrgtPos: invalidation-policy{data-element=EepMd61SecRwRtStLgrstInwdOtwdTrgtPos/Val, handle-invalid=DONT-INVALIDATE}
      data Val: type=UInt16
    EepMd61SecRwRtStLgrstInwdOtwdTrgtPos_S: invalidation-policy{data-element=EepMd61SecRwRtStLgrstInwdOtwdTrgtPos_S/Val, handle-invalid=DONT-INVALIDATE}
      data Val: type=UInt16
    EepMd61SecRwRtStLgrstUpwdDnwdTrgtPos: invalidation-policy{data-element=EepMd61SecRwRtStLgrstUpwdDnwdTrgtPos/Val, handle-invalid=DONT-INVALIDATE}
      data Val: type=UInt16
    EepMd61SecRwRtStLgrstUpwdDnwdTrgtPos_S: invalidation-policy{data-element=EepMd61SecRwRtStLgrstUpwdDnwdTrgtPos_S/Val, handle-invalid=DONT-INVALIDATE}
      data Val: type=UInt16
    EepMd61ThdRwLtStBkReclnTrgtPos: invalidation-policy{data-element=EepMd61ThdRwLtStBkReclnTrgtPos/Val, handle-invalid=DONT-INVALIDATE}
      data Val: type=UInt16
    EepMd61ThdRwLtStBkReclnTrgtPos_S: invalidation-policy{data-element=EepMd61ThdRwLtStBkReclnTrgtPos_S/Val, handle-invalid=DONT-INVALIDATE}
      data Val: type=UInt16
    EepMd61ThdRwLtStCshnFldTrgtPos: invalidation-policy{data-element=EepMd61ThdRwLtStCshnFldTrgtPos/Val, handle-invalid=DONT-INVALIDATE}
      data Val: type=UInt16
    EepMd61ThdRwLtStCshnFldTrgtPos_S: invalidation-policy{data-element=EepMd61ThdRwLtStCshnFldTrgtPos_S/Val, handle-invalid=DONT-INVALIDATE}
      data Val: type=UInt16
    EepMd61ThdRwLtStFwdBkwdTrgtPos: invalidation-policy{data-element=EepMd61ThdRwLtStFwdBkwdTrgtPos/Val, handle-invalid=DONT-INVALIDATE}
      data Val: type=UInt16
    EepMd61ThdRwLtStFwdBkwdTrgtPos_S: invalidation-policy{data-element=EepMd61ThdRwLtStFwdBkwdTrgtPos_S/Val, handle-invalid=DONT-INVALIDATE}
      data Val: type=UInt16
    EepMd61ThdRwRtStBkReclnTrgtPos: invalidation-policy{data-element=EepMd61ThdRwRtStBkReclnTrgtPos/Val, handle-invalid=DONT-INVALIDATE}
      data Val: type=UInt16
    EepMd61ThdRwRtStBkReclnTrgtPos_S: invalidation-policy{data-element=EepMd61ThdRwRtStBkReclnTrgtPos_S/Val, handle-invalid=DONT-INVALIDATE}
      data Val: type=UInt16
    EepMd61ThdRwRtStCshnFldTrgtPos: invalidation-policy{data-element=EepMd61ThdRwRtStCshnFldTrgtPos/Val, handle-invalid=DONT-INVALIDATE}
      data Val: type=UInt16
    EepMd61ThdRwRtStCshnFldTrgtPos_S: invalidation-policy{data-element=EepMd61ThdRwRtStCshnFldTrgtPos_S/Val, handle-invalid=DONT-INVALIDATE}
      data Val: type=UInt16
    EepMd61ThdRwRtStFwdBkwdTrgtPos: invalidation-policy{data-element=EepMd61ThdRwRtStFwdBkwdTrgtPos/Val, handle-invalid=DONT-INVALIDATE}
      data Val: type=UInt16
    EepMd61ThdRwRtStFwdBkwdTrgtPos_S: invalidation-policy{data-element=EepMd61ThdRwRtStFwdBkwdTrgtPos_S/Val, handle-invalid=DONT-INVALIDATE}
      data Val: type=UInt16
    EepMd62PassStBkReclnTrgtPos: invalidation-policy{data-element=EepMd62PassStBkReclnTrgtPos/Val, handle-invalid=DONT-INVALIDATE}
      data Val: type=UInt16
    EepMd62PassStBkReclnTrgtPos_S: invalidation-policy{data-element=EepMd62PassStBkReclnTrgtPos_S/Val, handle-invalid=DONT-INVALIDATE}
      data Val: type=UInt16
    EepMd62PassStCshnFldTrgtPos: invalidation-policy{data-element=EepMd62PassStCshnFldTrgtPos/Val, handle-invalid=DONT-INVALIDATE}
      data Val: type=UInt16
    EepMd62PassStCshnFldTrgtPos_S: invalidation-policy{data-element=EepMd62PassStCshnFldTrgtPos_S/Val, handle-invalid=DONT-INVALIDATE}
      data Val: type=UInt16
    EepMd62PassStFwdBkwdTrgtPos: invalidation-policy{data-element=EepMd62PassStFwdBkwdTrgtPos/Val, handle-invalid=DONT-INVALIDATE}
      data Val: type=UInt16
    EepMd62PassStFwdBkwdTrgtPos_S: invalidation-policy{data-element=EepMd62PassStFwdBkwdTrgtPos_S/Val, handle-invalid=DONT-INVALIDATE}
      data Val: type=UInt16
    EepMd62SecRwLtStBkReclnTrgtPos: invalidation-policy{data-element=EepMd62SecRwLtStBkReclnTrgtPos/Val, handle-invalid=DONT-INVALIDATE}
      data Val: type=UInt16
    EepMd62SecRwLtStBkReclnTrgtPos_S: invalidation-policy{data-element=EepMd62SecRwLtStBkReclnTrgtPos_S/Val, handle-invalid=DONT-INVALIDATE}
      data Val: type=UInt16
    EepMd62SecRwLtStCushFrntTrgtPos: invalidation-policy{data-element=EepMd62SecRwLtStCushFrntTrgtPos/Val, handle-invalid=DONT-INVALIDATE}
      data Val: type=UInt16
    EepMd62SecRwLtStCushFrntTrgtPos_S: invalidation-policy{data-element=EepMd62SecRwLtStCushFrntTrgtPos_S/Val, handle-invalid=DONT-INVALIDATE}
      data Val: type=UInt16
    EepMd62SecRwLtStFwdBkwdTrgtPos: invalidation-policy{data-element=EepMd62SecRwLtStFwdBkwdTrgtPos/Val, handle-invalid=DONT-INVALIDATE}
      data Val: type=UInt16
    EepMd62SecRwLtStFwdBkwdTrgtPos_S: invalidation-policy{data-element=EepMd62SecRwLtStFwdBkwdTrgtPos_S/Val, handle-invalid=DONT-INVALIDATE}
      data Val: type=UInt16
    EepMd62SecRwLtStLgrstInwdOtwdTrgtPos: invalidation-policy{data-element=EepMd62SecRwLtStLgrstInwdOtwdTrgtPos/Val, handle-invalid=DONT-INVALIDATE}
      data Val: type=UInt16
    EepMd62SecRwLtStLgrstInwdOtwdTrgtPos_S: invalidation-policy{data-element=EepMd62SecRwLtStLgrstInwdOtwdTrgtPos_S/Val, handle-invalid=DONT-INVALIDATE}
      data Val: type=UInt16
    EepMd62SecRwLtStLgrstUpwdDnwdTrgtPos: invalidation-policy{data-element=EepMd62SecRwLtStLgrstUpwdDnwdTrgtPos/Val, handle-invalid=DONT-INVALIDATE}
      data Val: type=UInt16
    EepMd62SecRwLtStLgrstUpwdDnwdTrgtPos_S: invalidation-policy{data-element=EepMd62SecRwLtStLgrstUpwdDnwdTrgtPos_S/Val, handle-invalid=DONT-INVALIDATE}
      data Val: type=UInt16
    EepMd62SecRwRtStBkReclnTrgtPos: invalidation-policy{data-element=EepMd62SecRwRtStBkReclnTrgtPos/Val, handle-invalid=DONT-INVALIDATE}
      data Val: type=UInt16
    EepMd62SecRwRtStBkReclnTrgtPos_S: invalidation-policy{data-element=EepMd62SecRwRtStBkReclnTrgtPos_S/Val, handle-invalid=DONT-INVALIDATE}
      data Val: type=UInt16
    EepMd62SecRwRtStCushFrntTrgtPos: invalidation-policy{data-element=EepMd62SecRwRtStCushFrntTrgtPos/Val, handle-invalid=DONT-INVALIDATE}
      data Val: type=UInt16
    EepMd62SecRwRtStCushFrntTrgtPos_S: invalidation-policy{data-element=EepMd62SecRwRtStCushFrntTrgtPos_S/Val, handle-invalid=DONT-INVALIDATE}
      data Val: type=UInt16
    EepMd62SecRwRtStFwdBkwdTrgtPos: invalidation-policy{data-element=EepMd62SecRwRtStFwdBkwdTrgtPos/Val, handle-invalid=DONT-INVALIDATE}
      data Val: type=UInt16
    EepMd62SecRwRtStFwdBkwdTrgtPos_S: invalidation-policy{data-element=EepMd62SecRwRtStFwdBkwdTrgtPos_S/Val, handle-invalid=DONT-INVALIDATE}
      data Val: type=UInt16
    EepMd62SecRwRtStLgrstInwdOtwdTrgtPos: invalidation-policy{data-element=EepMd62SecRwRtStLgrstInwdOtwdTrgtPos/Val, handle-invalid=DONT-INVALIDATE}
      data Val: type=UInt16
    EepMd62SecRwRtStLgrstInwdOtwdTrgtPos_S: invalidation-policy{data-element=EepMd62SecRwRtStLgrstInwdOtwdTrgtPos_S/Val, handle-invalid=DONT-INVALIDATE}
      data Val: type=UInt16
    EepMd62SecRwRtStLgrstUpwdDnwdTrgtPos: invalidation-policy{data-element=EepMd62SecRwRtStLgrstUpwdDnwdTrgtPos/Val, handle-invalid=DONT-INVALIDATE}
      data Val: type=UInt16
    EepMd62SecRwRtStLgrstUpwdDnwdTrgtPos_S: invalidation-policy{data-element=EepMd62SecRwRtStLgrstUpwdDnwdTrgtPos_S/Val, handle-invalid=DONT-INVALIDATE}
      data Val: type=UInt16
    EepMd62ThdRwLtStBkReclnTrgtPos: invalidation-policy{data-element=EepMd62ThdRwLtStBkReclnTrgtPos/Val, handle-invalid=DONT-INVALIDATE}
      data Val: type=UInt16
    EepMd62ThdRwLtStBkReclnTrgtPos_S: invalidation-policy{data-element=EepMd62ThdRwLtStBkReclnTrgtPos_S/Val, handle-invalid=DONT-INVALIDATE}
      data Val: type=UInt16
    EepMd62ThdRwLtStCshnFldTrgtPos: invalidation-policy{data-element=EepMd62ThdRwLtStCshnFldTrgtPos/Val, handle-invalid=DONT-INVALIDATE}
      data Val: type=UInt16
    EepMd62ThdRwLtStCshnFldTrgtPos_S: invalidation-policy{data-element=EepMd62ThdRwLtStCshnFldTrgtPos_S/Val, handle-invalid=DONT-INVALIDATE}
      data Val: type=UInt16
    EepMd62ThdRwLtStFwdBkwdTrgtPos: invalidation-policy{data-element=EepMd62ThdRwLtStFwdBkwdTrgtPos/Val, handle-invalid=DONT-INVALIDATE}
      data Val: type=UInt16
    EepMd62ThdRwLtStFwdBkwdTrgtPos_S: invalidation-policy{data-element=EepMd62ThdRwLtStFwdBkwdTrgtPos_S/Val, handle-invalid=DONT-INVALIDATE}
      data Val: type=UInt16
    EepMd62ThdRwRtStBkReclnTrgtPos: invalidation-policy{data-element=EepMd62ThdRwRtStBkReclnTrgtPos/Val, handle-invalid=DONT-INVALIDATE}
      data Val: type=UInt16
    EepMd62ThdRwRtStBkReclnTrgtPos_S: invalidation-policy{data-element=EepMd62ThdRwRtStBkReclnTrgtPos_S/Val, handle-invalid=DONT-INVALIDATE}
      data Val: type=UInt16
    EepMd62ThdRwRtStCshnFldTrgtPos: invalidation-policy{data-element=EepMd62ThdRwRtStCshnFldTrgtPos/Val, handle-invalid=DONT-INVALIDATE}
      data Val: type=UInt16
    EepMd62ThdRwRtStCshnFldTrgtPos_S: invalidation-policy{data-element=EepMd62ThdRwRtStCshnFldTrgtPos_S/Val, handle-invalid=DONT-INVALIDATE}
      data Val: type=UInt16
    EepMd62ThdRwRtStFwdBkwdTrgtPos: invalidation-policy{data-element=EepMd62ThdRwRtStFwdBkwdTrgtPos/Val, handle-invalid=DONT-INVALIDATE}
      data Val: type=UInt16
    EepMd62ThdRwRtStFwdBkwdTrgtPos_S: invalidation-policy{data-element=EepMd62ThdRwRtStFwdBkwdTrgtPos_S/Val, handle-invalid=DONT-INVALIDATE}
      data Val: type=UInt16
    IfVeSMSbPassStFldUpwdDnwdMovConfig: invalidation-policy{data-element=IfVeSMSbPassStFldUpwdDnwdMovConfig/Val, handle-invalid=DONT-INVALIDATE}
      data Val: type=Boolean
    IfVeSMSbSecRwRtSLgrstExpdMovConfig: invalidation-policy{data-element=IfVeSMSbSecRwRtSLgrstExpdMovConfig/Val, handle-invalid=DONT-INVALIDATE}
      data Val: type=Boolean
    IfVeSMSuPassStFldUpwdDnwdPos: invalidation-policy{data-element=IfVeSMSuPassStFldUpwdDnwdPos/Val, handle-invalid=DONT-INVALIDATE}
      data Val: type=UInt16
    MdReq: invalidation-policy{data-element=MdReq/Val, handle-invalid=DONT-INVALIDATE}
      data Val: type=Boolean
    modestate32: invalidation-policy{data-element=modestate32/Val, handle-invalid=DONT-INVALIDATE}
      data Val: type=UInt32
    PercPos: invalidation-policy{data-element=PercPos/Val, handle-invalid=DONT-INVALIDATE}
      data Val: type=UInt16
    PercPosV: invalidation-policy{data-element=PercPosV/Val, handle-invalid=DONT-INVALIDATE}
      data Val: type=Boolean
    StPassCmprtRestMdMemVirtCtrlReqMdadjust: invalidation-policy{data-element=StPassCmprtRestMdMemVirtCtrlReqMdadjust/Val, handle-invalid=DONT-INVALIDATE}
      data Val: type=UInt8
    TrgtIsFld: invalidation-policy{data-element=TrgtIsFld/Val, handle-invalid=DONT-INVALIDATE}
      data Val: type=Boolean
    TrgtPosCalibArray: invalidation-policy{data-element=TrgtPosArray, handle-invalid=DONT-INVALIDATE}
      data TrgtPosArray: type=TrgtPosCalibArray  # 0:Pos 1:Max 2:Min
package /PATAC/MSM/PortInterfaces
  31 x sender receiver interface:
    IfVeSMSbPassStBkReclnUpwdDnwdMovConfig: invalidation-policy{data-element=IfVeSMSbPassStBkReclnUpwdDnwdMovConfig/Val, handle-invalid=DONT-INVALIDATE}
      data Val: type=Boolean
    IfVeSMSbPassStFrwdBkwdMovConfig: invalidation-policy{data-element=IfVeSMSbPassStFrwdBkwdMovConfig/Val, handle-invalid=DONT-INVALIDATE}
      data Val: type=Boolean
    IfVeSMSbSecRwLtSLgrstExpdMovConfig: invalidation-policy{data-element=IfVeSMSbSecRwLtSLgrstExpdMovConfig/Val, handle-invalid=DONT-INVALIDATE}
      data Val: type=Boolean
    IfVeSMSbSecRwLtStBkReclnUpwdDnwdMovConfig: invalidation-policy{data-element=IfVeSMSbSecRwLtStBkReclnUpwdDnwdMovConfig/Val, handle-invalid=DONT-INVALIDATE}
      data Val: type=Boolean
    IfVeSMSbSecRwLtStFrwdBkwdMovConfig: invalidation-policy{data-element=IfVeSMSbSecRwLtStFrwdBkwdMovConfig/Val, handle-invalid=DONT-INVALIDATE}
      data Val: type=Boolean
    IfVeSMSbSecRwLtStLgrstUpwdMovConfig: invalidation-policy{data-element=IfVeSMSbSecRwLtStLgrstUpwdMovConfig/Val, handle-invalid=DONT-INVALIDATE}
      data Val: type=Boolean
    IfVeSMSbSecRwRtStBkReclnUpwdDnwdMovConfig: invalidation-policy{data-element=IfVeSMSbSecRwRtStBkReclnUpwdDnwdMovConfig/Val, handle-invalid=DONT-INVALIDATE}
      data Val: type=Boolean
    IfVeSMSbSecRwRtStFrwdBkwdMovConfig: invalidation-policy{data-element=IfVeSMSbSecRwRtStFrwdBkwdMovConfig/Val, handle-invalid=DONT-INVALIDATE}
      data Val: type=Boolean
    IfVeSMSbSecRwRtStLgrstUpwdMovConfig: invalidation-policy{data-element=IfVeSMSbSecRwRtStLgrstUpwdMovConfig/Val, handle-invalid=DONT-INVALIDATE}
      data Val: type=Boolean
    IfVeSMSbThdRwLtStBkReclnUpwdDnwdMovConfig: invalidation-policy{data-element=IfVeSMSbThdRwLtStBkReclnUpwdDnwdMovConfig/Val, handle-invalid=DONT-INVALIDATE}
      data Val: type=Boolean
    IfVeSMSbThdRwLtStCshnFldUpwdDnwdMovConfig: invalidation-policy{data-element=IfVeSMSbThdRwLtStCshnFldUpwdDnwdMovConfig/Val, handle-invalid=DONT-INVALIDATE}
      data Val: type=Boolean
    IfVeSMSbThdRwLtStFrwdBkwdMovConfig: invalidation-policy{data-element=IfVeSMSbThdRwLtStFrwdBkwdMovConfig/Val, handle-invalid=DONT-INVALIDATE}
      data Val: type=Boolean
    IfVeSMSbThdRwRtStBkReclnUpwdDnwdMovConfig: invalidation-policy{data-element=IfVeSMSbThdRwRtStBkReclnUpwdDnwdMovConfig/Val, handle-invalid=DONT-INVALIDATE}
      data Val: type=Boolean
    IfVeSMSbThdRwRtStCshnFldUpwdDnwdMovConfig: invalidation-policy{data-element=IfVeSMSbThdRwRtStCshnFldUpwdDnwdMovConfig/Val, handle-invalid=DONT-INVALIDATE}
      data Val: type=Boolean
    IfVeSMSbThdRwRtStFrwdBkwdMovConfig: invalidation-policy{data-element=IfVeSMSbThdRwRtStFrwdBkwdMovConfig/Val, handle-invalid=DONT-INVALIDATE}
      data Val: type=Boolean
    IfVeSMSuPassStBkReclnUpwdDnwdPos: invalidation-policy{data-element=IfVeSMSuPassStBkReclnUpwdDnwdPos/Val, handle-invalid=DONT-INVALIDATE}
      data Val: type=UInt16
    IfVeSMSuPassStFrwdBkwdPos: invalidation-policy{data-element=IfVeSMSuPassStFrwdBkwdPos/Val, handle-invalid=DONT-INVALIDATE}
      data Val: type=UInt16
    IfVeSMSuSecRwLtStBkReclnUpwdDnwdPos: invalidation-policy{data-element=IfVeSMSuSecRwLtStBkReclnUpwdDnwdPos/Val, handle-invalid=DONT-INVALIDATE}
      data Val: type=UInt16
    IfVeSMSuSecRwLtStFrwdBkwdPos: invalidation-policy{data-element=IfVeSMSuSecRwLtStFrwdBkwdPos/Val, handle-invalid=DONT-INVALIDATE}
      data Val: type=UInt16
    IfVeSMSuSecRwLtStLgrstOtwdInwdPos: invalidation-policy{data-element=IfVeSMSuSecRwLtStLgrstOtwdInwdPos/Val, handle-invalid=DONT-INVALIDATE}
      data Val: type=UInt16
    IfVeSMSuSecRwLtStLgrstOtwdInwdPosV: invalidation-policy{data-element=IfVeSMSuSecRwLtStLgrstOtwdInwdPosV/Val, handle-invalid=DONT-INVALIDATE}
      data Val: type=Boolean
    IfVeSMSuSecRwLtStLgrstUpwdDnwdPos: invalidation-policy{data-element=IfVeSMSuSecRwLtStLgrstUpwdDnwdPos/Val, handle-invalid=DONT-INVALIDATE}
      data Val: type=UInt16
    IfVeSMSuSecRwRtStBkReclnUpwdDnwdPos: invalidation-policy{data-element=IfVeSMSuSecRwRtStBkReclnUpwdDnwdPos/Val, handle-invalid=DONT-INVALIDATE}
      data Val: type=UInt16
    IfVeSMSuSecRwRtStLgrstOtwdInwdPos: invalidation-policy{data-element=IfVeSMSuSecRwRtStLgrstOtwdInwdPos/Val, handle-invalid=DONT-INVALIDATE}
      data Val: type=UInt16
    IfVeSMSuSecRwRtStLgrstOtwdInwdPosV: invalidation-policy{data-element=IfVeSMSuSecRwRtStLgrstOtwdInwdPosV/Val, handle-invalid=DONT-INVALIDATE}
      data Val: type=Boolean
    IfVeSMSuSecRwRtStLgrstUpwdDnwdPos: invalidation-policy{data-element=IfVeSMSuSecRwRtStLgrstUpwdDnwdPos/Val, handle-invalid=DONT-INVALIDATE}
      data Val: type=UInt16
    IfVeSMSuThdRwLtStBkReclnUpwdDnwdPos: invalidation-policy{data-element=IfVeSMSuThdRwLtStBkReclnUpwdDnwdPos/Val, handle-invalid=DONT-INVALIDATE}
      data Val: type=UInt16
    IfVeSMSuThdRwLtStFrwdBkwdPos: invalidation-policy{data-element=IfVeSMSuThdRwLtStFrwdBkwdPos/Val, handle-invalid=DONT-INVALIDATE}
      data Val: type=UInt16
    IfVeSMSuThdRwRStFrwdBkwdPos: invalidation-policy{data-element=IfVeSMSuThdRwRStFrwdBkwdPos/Val, handle-invalid=DONT-INVALIDATE}
      data Val: type=UInt16
    IfVeSMSuThdRwRtStBkReclnUpwdDnwdPos: invalidation-policy{data-element=IfVeSMSuThdRwRtStBkReclnUpwdDnwdPos/Val, handle-invalid=DONT-INVALIDATE}
      data Val: type=UInt16
    SeatConfig: invalidation-policy{data-element=SeatConfig/Val, handle-invalid=DONT-INVALIDATE}
      data Val: type=Boolean
